VERSION ""

NS_ :

BS_:

BU_: MPC

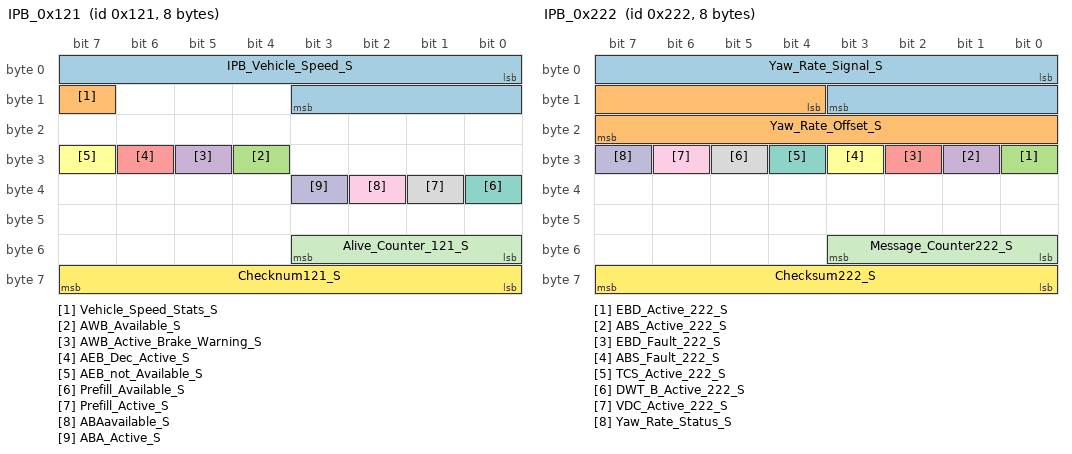
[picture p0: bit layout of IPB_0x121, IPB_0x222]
BO_ 289 IPB_0x121: 8 Vector__XXX
 SG_ IPB_Vehicle_Speed_S : 0|12@1+ (0.06875,0) [0|281.4625] "km/h"  MPC
 SG_ Vehicle_Speed_Stats_S : 15|1@1+ (1,0) [0|1] ""  MPC
 SG_ AWB_Available_S : 28|1@1+ (1,0) [0|1] ""  MPC
 SG_ AWB_Active_Brake_Warning_S : 29|1@1+ (1,0) [0|1] ""  MPC
 SG_ AEB_Dec_Active_S : 30|1@1+ (1,0) [0|1] ""  MPC
 SG_ AEB_not_Available_S : 31|1@1+ (1,0) [0|1] ""  MPC
 SG_ Prefill_Available_S : 32|1@1+ (1,0) [0|1] ""  MPC
 SG_ Prefill_Active_S : 33|1@1+ (1,0) [0|1] ""  MPC
 SG_ ABAavailable_S : 34|1@1+ (1,0) [0|1] ""  MPC
 SG_ ABA_Active_S : 35|1@1+ (1,0) [0|1] ""  MPC
 SG_ Alive_Counter_121_S : 48|4@1+ (1,0) [0|15] ""  MPC
 SG_ Checknum121_S : 56|8@1+ (1,0) [0|255] ""  MPC

BO_ 291 IPB_0x123: 8 Vector__XXX
 SG_ HHC_Fault_S : 0|1@1+ (1,0) [0|1] "" Vector__XXX
 SG_ ATS_Ctrl_Status_S : 1|1@1+ (1,0) [0|1] "" Vector__XXX
 SG_ Brake_Fluid_Warning_S : 2|2@1+ (1,0) [0|3] "" Vector__XXX
 SG_ IPB_Sport_Model_S : 4|1@1+ (1,0) [0|1] "" Vector__XXX
 SG_ IPB_Func_Mode_S : 5|2@1+ (1,0) [0|3] "" Vector__XXX
 SG_ Mmot_Tar_Fast_FA_S : 8|16@1+ (1,-12000) [-12000|12000] "NM" Vector__XXX
 SG_ Mmot_Tar_Slow_S : 24|16@1+ (1,-12000) [-12000|12000] "NM" Vector__XXX
 SG_ HDC_Failure_S : 40|1@1+ (1,0) [0|1] "" Vector__XXX
 SG_ HDC_CtrlStatus_S : 41|2@1+ (1,0) [0|3] ""  MPC
 SG_ Brake_Pedal_Status_S : 43|2@1+ (1,0) [0|3] ""  MPC
 SG_ Basc_Front_S : 45|1@1+ (1,0) [0|1] "" Vector__XXX
 SG_ Clutch_Pedal_Status_S : 46|1@1+ (1,0) [0|1] "" Vector__XXX
 SG_ ACMH_Fault_S : 47|1@1+ (1,0) [0|1] "" Vector__XXX
 SG_ Counter123_S : 48|4@1+ (1,0) [0|15] ""  MPC
 SG_ ESP_OFF_S : 52|1@1+ (1,0) [0|1] ""  MPC
 SG_ ESP_Active_S : 53|1@1+ (1,0) [0|1] ""  MPC
 SG_ TCS_Fault_S : 54|1@1+ (1,0) [0|1] ""  MPC
 SG_ VDC_Fault_S : 55|1@1+ (1,0) [0|1] ""  MPC
 SG_ Checksum123_S : 56|8@1+ (1,0) [0|255] ""  MPC

BO_ 546 IPB_0x222: 8 Vector__XXX
 SG_ Yaw_Rate_Signal_S : 0|12@1+ (0.002132603,-2.0943) [-2.0943|2.0943] "rad/s"  MPC
 SG_ Yaw_Rate_Offset_S : 12|12@1+ (0.002132603,-0.13) [-0.13|0.13] "rad/s"  MPC
 SG_ EBD_Active_222_S : 24|1@1+ (1,0) [0|1] ""  MPC
 SG_ ABS_Active_222_S : 25|1@1+ (1,0) [0|1] ""  MPC
 SG_ EBD_Fault_222_S : 26|1@1+ (1,0) [0|1] ""  MPC
 SG_ ABS_Fault_222_S : 27|1@1+ (1,0) [0|1] ""  MPC
 SG_ TCS_Active_222_S : 28|1@1+ (1,0) [0|1] ""  MPC
 SG_ DWT_B_Active_222_S : 29|1@1+ (1,0) [0|1] ""  MPC
 SG_ VDC_Active_222_S : 30|1@1+ (1,0) [0|1] ""  MPC
 SG_ Yaw_Rate_Status_S : 31|1@1+ (1,0) [0|1] ""  MPC
 SG_ Message_Counter222_S : 48|4@1+ (1,0) [0|15] ""  MPC
 SG_ Checksum222_S : 56|8@1+ (1,0) [0|255] ""  MPC

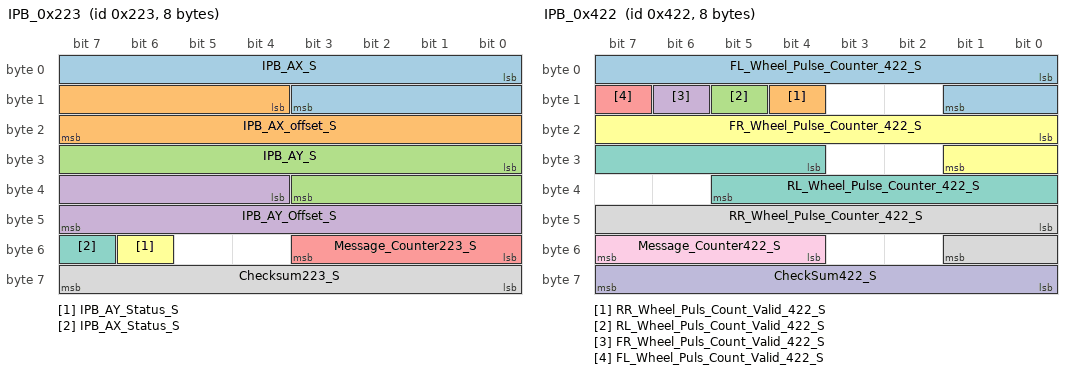
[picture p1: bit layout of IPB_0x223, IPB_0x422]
BO_ 547 IPB_0x223: 8 Vector__XXX
 SG_ IPB_AX_S : 0|12@1+ (0.027126736,-21.593) [-21.593|21.593] "m/s2"  MPC
 SG_ IPB_AX_offset_S : 12|12@1+ (0.027126736,-21.593) [-21.593|21.593] "m/s2"  MPC
 SG_ IPB_AY_S : 24|12@1+ (0.027126736,-21.593) [-21.593|21.593] "m/s2"  MPC
 SG_ IPB_AY_Offset_S : 36|12@1+ (0.027126736,-21.593) [-21.593|21.593] "m/s2"  MPC
 SG_ Message_Counter223_S : 48|4@1+ (1,0) [0|15] ""  MPC
 SG_ IPB_AY_Status_S : 54|1@1+ (1,0) [0|1] ""  MPC
 SG_ IPB_AX_Status_S : 55|1@1+ (1,0) [0|1] ""  MPC
 SG_ Checksum223_S : 56|8@1+ (1,0) [0|255] ""  MPC

BO_ 544 IPB_0x220: 8 Vector__XXX
 SG_ RR_Wheel_Drive_Direction_S : 0|2@1+ (1,0) [0|3] ""  MPC
 SG_ RL_Wheel_Drive_Direction_S : 2|2@1+ (1,0) [0|3] ""  MPC
 SG_ FR_Wheel_Drive_Direction_S : 4|2@1+ (1,0) [0|3] ""  MPC
 SG_ FL_Wheel_Drive_Direction_S : 6|2@1+ (1,0) [0|3] ""  MPC
 SG_ Active_Vehicle_Hold_S : 8|1@1+ (1,0) [0|1] ""  MPC
 SG_ VLC_Available_S : 9|1@1+ (1,0) [0|1] ""  MPC
 SG_ VLC_Active_S : 10|1@1+ (1,0) [0|1] ""  MPC
 SG_ VLC_Fail_S : 11|1@1+ (1,0) [0|1] ""  MPC
 SG_ No_Brake_Force_S : 12|1@1+ (1,0) [0|1] ""  MPC
 SG_ IPB_Request_EPB_S : 13|2@1+ (1,0) [0|3] "" Vector__XXX
 SG_ QDC_ACC_S : 15|1@1+ (1,0) [0|1] ""  MPC
 SG_ ECD_Temp_Off_S : 16|1@1+ (1,0) [0|1] ""  MPC
 SG_ Vlc_Prevent_Fuel_Cut_Off_S : 17|1@1+ (1,0) [0|1] "" Vector__XXX
 SG_ Vehicle_Stand_Still_S : 18|2@1+ (1,0) [0|3] ""  MPC
 SG_ FL_Wheel_Drive_Direct_Stat_S : 20|1@1+ (1,0) [0|1] ""  MPC
 SG_ FR_Wheel_Drive_Direct_Stat_S : 21|1@1+ (1,0) [0|1] ""  MPC
 SG_ RL_Wheel_Drive_Direct_Stat_S : 22|1@1+ (1,0) [0|1] ""  MPC
 SG_ RR_Wheel_Drive_Direct_Stat_S : 23|1@1+ (1,0) [0|1] ""  MPC
 SG_ VLC_Internal_Targ_Accel_S : 24|8@1+ (0.05,-7) [-7|5.75] "m/s2"  MPC
 SG_ VLC_Torque_Request_Value_S : 32|16@1+ (1,-12000) [-12000|12000] "NM" Vector__XXX
 SG_ Message_Counter220_S : 48|4@1+ (1,0) [0|15] ""  MPC
 SG_ VLC_Torque_Request_Status_S : 52|1@1+ (1,0) [0|1] ""  MPC
 SG_ CDD_Available_S : 53|1@1+ (1,0) [0|1] ""  MPC
 SG_ CDD_Active_S : 54|1@1+ (1,0) [0|1] ""  MPC
 SG_ CDD_Fail_S : 55|1@1+ (1,0) [0|1] ""  MPC
 SG_ CheckSum220_S : 56|8@1+ (1,0) [0|255] ""  MPC

BO_ 1058 IPB_0x422: 8 Vector__XXX
 SG_ FL_Wheel_Pulse_Counter_422_S : 0|10@1+ (1,0) [0|1022] ""  MPC
 SG_ RR_Wheel_Puls_Count_Valid_422_S : 12|1@1+ (1,0) [0|1] ""  MPC
 SG_ RL_Wheel_Puls_Count_Valid_422_S : 13|1@1+ (1,0) [0|1] ""  MPC
 SG_ FR_Wheel_Puls_Count_Valid_422_S : 14|1@1+ (1,0) [0|1] ""  MPC
 SG_ FL_Wheel_Puls_Count_Valid_422_S : 15|1@1+ (1,0) [0|1] ""  MPC
 SG_ FR_Wheel_Pulse_Counter_422_S : 16|10@1+ (1,0) [0|1022] ""  MPC
 SG_ RL_Wheel_Pulse_Counter_422_S : 28|10@1+ (1,0) [0|1022] ""  MPC
 SG_ RR_Wheel_Pulse_Counter_422_S : 40|10@1+ (1,0) [0|1022] ""  MPC
 SG_ Message_Counter422_S : 52|4@1+ (1,0) [0|15] ""  MPC
 SG_ CheckSum422_S : 56|8@1+ (1,0) [0|255] ""  MPC

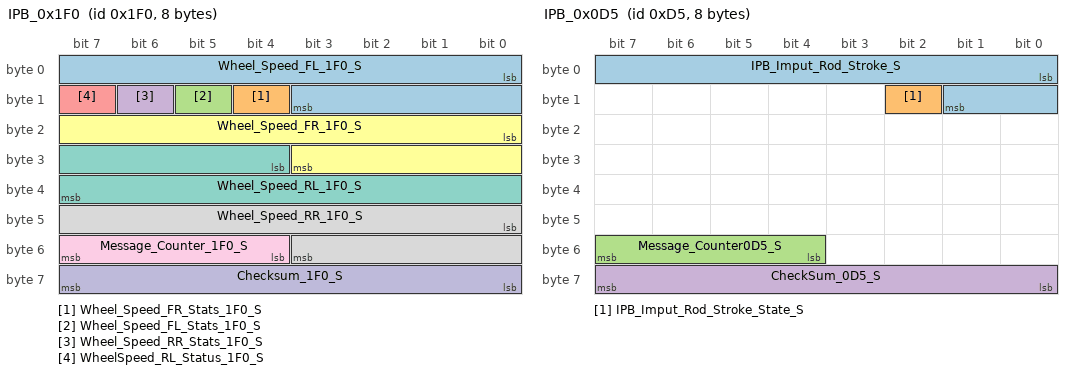
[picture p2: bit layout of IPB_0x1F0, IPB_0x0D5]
BO_ 496 IPB_0x1F0: 8 Vector__XXX
 SG_ Wheel_Speed_FL_1F0_S : 0|12@1+ (0.06875,0) [0|281.4625] "km/h"  MPC
 SG_ Wheel_Speed_FR_Stats_1F0_S : 12|1@1+ (1,0) [0|1] ""  MPC
 SG_ Wheel_Speed_FL_Stats_1F0_S : 13|1@1+ (1,0) [0|1] ""  MPC
 SG_ Wheel_Speed_RR_Stats_1F0_S : 14|1@1+ (1,0) [0|1] ""  MPC
 SG_ WheelSpeed_RL_Status_1F0_S : 15|1@1+ (1,0) [0|1] ""  MPC
 SG_ Wheel_Speed_FR_1F0_S : 16|12@1+ (0.06875,0) [0|281.4625] "km/h"  MPC
 SG_ Wheel_Speed_RL_1F0_S : 28|12@1+ (0.06875,0) [0|281.4625] "km/h"  MPC
 SG_ Wheel_Speed_RR_1F0_S : 40|12@1+ (0.06875,0) [0|281.4625] "km/h"  MPC
 SG_ Message_Counter_1F0_S : 52|4@1+ (1,0) [0|15] ""  MPC
 SG_ Checksum_1F0_S : 56|8@1+ (1,0) [0|255] ""  MPC

BO_ 213 IPB_0x0D5: 8 Vector__XXX
 SG_ IPB_Imput_Rod_Stroke_S : 0|10@1+ (0.05,-5) [-5|46.15] "mm"  MPC
 SG_ IPB_Imput_Rod_Stroke_State_S : 10|1@1+ (1,0) [0|1] ""  MPC
 SG_ Message_Counter0D5_S : 52|4@1+ (1,0) [0|15] ""  MPC
 SG_ CheckSum_0D5_S : 56|8@1+ (1,0) [0|255] ""  MPC

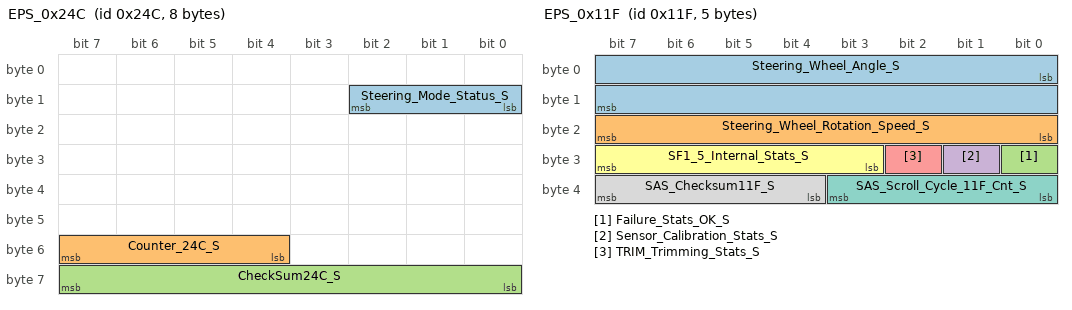
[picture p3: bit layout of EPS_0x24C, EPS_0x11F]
BO_ 588 EPS_0x24C: 8 Vector__XXX
 SG_ Steering_Mode_Status_S : 8|3@1+ (1,0) [0|15] ""  MPC
 SG_ Counter_24C_S : 52|4@1+ (1,0) [0|15] ""  MPC
 SG_ CheckSum24C_S : 56|8@1+ (1,0) [0|255] ""  MPC

BO_ 287 EPS_0x11F: 5 Vector__XXX
 SG_ Steering_Wheel_Angle_S : 0|16@1- (0.1,0) [-780|779.9] "度"  MPC
 SG_ Steering_Wheel_Rotation_Speed_S : 16|8@1+ (4,0) [0|1016] "°/s"  MPC
 SG_ Failure_Stats_OK_S : 24|1@1+ (1,0) [0|1] ""  MPC
 SG_ Sensor_Calibration_Stats_S : 25|1@1+ (1,0) [0|1] ""  MPC
 SG_ TRIM_Trimming_Stats_S : 26|1@1+ (1,0) [0|1] ""  MPC
 SG_ SF1_5_Internal_Stats_S : 27|5@1+ (1,0) [0|31] ""  MPC
 SG_ SAS_Scroll_Cycle_11F_Cnt_S : 32|4@1+ (1,0) [0|15] ""  MPC
 SG_ SAS_Checksum11F_S : 36|4@1+ (1,0) [0|15] ""  MPC

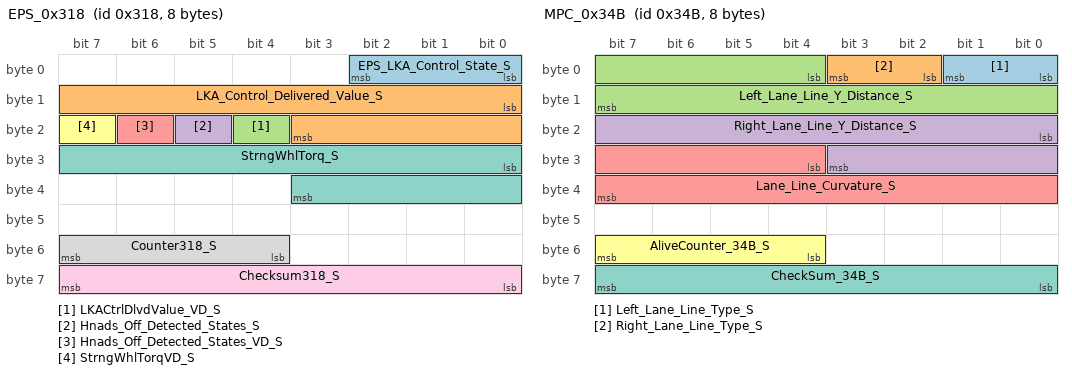
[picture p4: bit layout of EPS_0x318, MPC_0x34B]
BO_ 792 EPS_0x318: 8 Vector__XXX
 SG_ EPS_LKA_Control_State_S : 0|3@1+ (1,0) [0|7] ""  MPC
 SG_ LKA_Control_Delivered_Value_S : 8|12@1- (0.01,0) [-5|-5] "Nm"  MPC
 SG_ LKACtrlDlvdValue_VD_S : 20|1@1+ (1,0) [0|1] ""  MPC
 SG_ Hnads_Off_Detected_States_S : 21|1@1+ (1,0) [0|1] ""  MPC
 SG_ Hnads_Off_Detected_States_VD_S : 22|1@1+ (1,0) [0|1] ""  MPC
 SG_ StrngWhlTorqVD_S : 23|1@1+ (1,0) [0|1] ""  MPC
 SG_ StrngWhlTorq_S : 24|12@1- (0.01,0) [-12.5|12.5] "Nm"  MPC
 SG_ Counter318_S : 52|4@1+ (1,0) [0|15] ""  MPC
 SG_ Checksum318_S : 56|8@1+ (1,0) [0|255] ""  MPC

BO_ 790 MPC_0x316: 8 MPC
 SG_ RSF_Output_Speed_Limit_S : 40|8@1+ (1,0) [0|255] "" Vector__XXX
 SG_ RSF_function_status_S : 29|3@1+ (1,0) [0|3] "" Vector__XXX
 SG_ RSF_Output_Speed_Limit_Unit_S : 32|2@1+ (1,0) [0|3] "" Vector__XXX
 SG_ Over_Temperature : 15|1@1+ (1,0) [0|1] "" Vector__XXX
 SG_ Left_Line_Tracking_Status_S : 4|2@1+ (1,0) [0|3] "" Vector__XXX
 SG_ Lane_Assistant_Mode_Status_S : 6|2@1+ (1,0) [0|3] "" Vector__XXX
 SG_ LKS_Sensitivity_S : 8|2@1+ (1,0) [0|3] "" Vector__XXX
 SG_ MPC_Take_Over_Req_S : 10|1@1+ (1,0) [0|1] "" Vector__XXX
 SG_ LDP_LDW_Camera_Blocked_S : 11|1@1+ (1,0) [0|1] "" Vector__XXX
 SG_ LDP_Fault_S : 12|1@1+ (1,0) [0|1] "" Vector__XXX
 SG_ LDW_fault1_S : 13|1@1+ (1,0) [0|1] "" Vector__XXX
 SG_ ACC_AEB_Camera_Blocked_Infro_S : 14|1@1+ (1,0) [0|1] "" Vector__XXX
 SG_ Output_LKS_torque_request_S : 16|11@1- (0.01,0) [-10.24|10.23] "Nm" Vector__XXX
 SG_ LKS_torque_request_staus_S : 27|2@1+ (1,0) [0|3] "" Vector__XXX
 SG_ Right_Line_Tracking_Stats_S : 34|2@1+ (1,0) [0|3] "" Vector__XXX
 SG_ TJA_ICA_function_status_S : 36|3@1+ (1,0) [0|7] "" Vector__XXX
 SG_ ALL_Function_Camera_Bloc_Infro_S : 39|1@1+ (1,0) [0|1] "" Vector__XXX
 SG_ LDW_Warning_Mode_Stats_S : 48|2@1+ (1,0) [0|3] "" Vector__XXX
 SG_ MPC_Take_Over_Req1_S : 50|2@1+ (1,0) [0|3] "" Vector__XXX
 SG_ Message_Alive_Counter316_S : 52|4@1+ (1,0) [0|15] "" Vector__XXX
 SG_ Messge_Checksum316_S : 56|8@1+ (1,0) [0|255] "" Vector__XXX

BO_ 1074 MPC_0x432: 8 MPC
 SG_ ADS_System_Status_S : 28|4@1+ (1,0) [0|15] "" Vector__XXX
 SG_ CSW_Assemble_Status_S : 27|1@1+ (1,0) [0|1] "" Vector__XXX
 SG_ UNP_Assemble_Status_S : 26|1@1+ (1,0) [0|1] "" Vector__XXX
 SG_ FCTB_Assemble_Status_S : 17|1@1+ (1,0) [0|1] "" Vector__XXX
 SG_ ACC_Assemble_Status_S : 0|1@1+ (1,0) [0|1] "" Vector__XXX
 SG_ AEB_Assemble_Status_S : 1|1@1+ (1,0) [0|1] "" Vector__XXX
 SG_ FCW_Assemble_Status_S : 2|1@1+ (1,0) [0|1] "" Vector__XXX
 SG_ HMA_Assemble_Status_S : 3|1@1+ (1,0) [0|1] "" Vector__XXX
 SG_ LDW_Assemble_Status_S : 4|1@1+ (1,0) [0|1] "" Vector__XXX
 SG_ LKS_Assemble_Status_S : 5|1@1+ (1,0) [0|1] "" Vector__XXX
 SG_ TSR_Assemble_Status_S : 6|1@1+ (1,0) [0|1] "" Vector__XXX
 SG_ TJA_ICA_Assemble_Status_S : 7|1@1+ (1,0) [0|1] "" Vector__XXX
 SG_ Module_Manufacturer_S : 8|4@1+ (1,0) [0|15] "" Vector__XXX
 SG_ LDW_Warning_Conf_Exchange_S : 12|1@1+ (1,0) [0|1] "" Vector__XXX
 SG_ TJA_ICA_SoftKeys_S : 13|1@1+ (1,0) [0|1] "" Vector__XXX
 SG_ LDP_Assemble_Status_S : 14|1@1+ (1,0) [0|1] "" Vector__XXX
 SG_ ELK_Assemble_Status_S : 15|1@1+ (1,0) [0|1] "" Vector__XXX
 SG_ FCTA_Assemble_Status_S : 16|1@1+ (1,0) [0|1] "" Vector__XXX
 SG_ ISLI_Assemble_Statue_S : 18|1@1+ (1,0) [0|1] "" Vector__XXX
 SG_ HNP_Assemble_Status_S : 19|1@1+ (1,0) [0|1] "" Vector__XXX
 SG_ ILCA_Assemble_Status_S : 20|1@1+ (1,0) [0|1] "" Vector__XXX
 SG_ TLA_Assemble_Status_S : 21|1@1+ (1,0) [0|1] "" Vector__XXX
 SG_ ISLC_Assemble_Status_S : 22|1@1+ (1,0) [0|1] "" Vector__XXX
 SG_ ESA_Assemble_Status_S : 23|1@1+ (1,0) [0|1] "" Vector__XXX
 SG_ FCW_UI_Assemble_Status_S : 24|1@1+ (1,0) [0|1] "" Vector__XXX
 SG_ Meter_Display_Mode_S : 25|1@1+ (1,0) [0|1] "" Vector__XXX

BO_ 884 MPC_0x374: 8 MPC
 SG_ Target_Type_374s5_S m5 : 44|4@1+ (1,0) [0|15] "" Vector__XXX
 SG_ Target_State_B1_374s5_S m5 : 43|1@1+ (1,0) [0|1] "" Vector__XXX
 SG_ Target_State_B6_374s5_S m5 : 40|2@1+ (1,0) [0|3] "" Vector__XXX
 SG_ Lock_Target_Ordinate_374s5_S m5 : 16|8@1+ (1,-100) [-100|100] "pot" Vector__XXX
 SG_ Lock_Target_Abscissa_374s5_S m5 : 8|8@1+ (1,-100) [-100|100] "pot" Vector__XXX
 SG_ Goal_Late_Relative_Spd_374s5_S m5 : 32|8@1+ (1,0) [0|254] "km/h" Vector__XXX
 SG_ Goal_Length_Relative_Spd_374s5_S m5 : 24|8@1+ (1,0) [0|254] "km/h" Vector__XXX
 SG_ AliveCounter_374s5_S m5 : 52|4@1+ (1,0) [0|15] "" Vector__XXX
 SG_ CheckSum_374s5_S m5 : 56|8@1+ (1,0) [0|255] "" Vector__XXX
 SG_ Child_ID_374_S M : 0|8@1+ (1,0) [0|255] "" Vector__XXX
 SG_ Lock_Target_Abscissa_374s1_S m1 : 8|8@1+ (1,-100) [-100|100] "pot" Vector__XXX
 SG_ Lock_Target_Ordinate_374s1_S m1 : 16|8@1+ (1,-100) [-100|100] "pot" Vector__XXX
 SG_ Goal_Length_Relative_Spd_374s1_S m1 : 24|8@1+ (1,0) [0|254] "km/h" Vector__XXX
 SG_ Goal_Late_Relative_Spd_374s1_S m1 : 32|8@1+ (1,0) [0|254] "km/h" Vector__XXX
 SG_ Target_State_B6_374s1_S m1 : 40|2@1+ (1,0) [0|3] "" Vector__XXX
 SG_ Target_State_B1_374s1_S m1 : 43|1@1+ (1,0) [0|1] "" Vector__XXX
 SG_ Target_Type_374s1_S m1 : 44|4@1+ (1,0) [0|15] "" Vector__XXX
 SG_ AliveCounter_374s1_S m1 : 52|4@1+ (1,0) [0|15] "" Vector__XXX
 SG_ CheckSum_374s1_S m1 : 56|8@1+ (1,0) [0|255] "" Vector__XXX
 SG_ Lock_Target_Abscissa_374s2_S m2 : 8|8@1+ (1,-100) [-100|100] "pot" Vector__XXX
 SG_ Lock_Target_Ordinate_374s2_S m2 : 16|8@1+ (1,-100) [-100|100] "pot" Vector__XXX
 SG_ Goal_Length_Relative_Spd_374s2_S m2 : 24|8@1+ (1,0) [0|254] "km/h" Vector__XXX
 SG_ Goal_Late_Relative_Spd_374s2_S m2 : 32|8@1+ (1,0) [0|254] "km/h" Vector__XXX
 SG_ Target_State_B6_374s2_S m2 : 40|2@1+ (1,0) [0|3] "" Vector__XXX
 SG_ Target_State_B1_374s2_S m2 : 43|1@1+ (1,0) [0|1] "" Vector__XXX
 SG_ Target_Type_374s2_S m2 : 44|4@1+ (1,0) [0|15] "" Vector__XXX
 SG_ AliveCounter_374s2_S m2 : 52|4@1+ (1,0) [0|15] "" Vector__XXX
 SG_ CheckSum_374s2_S m2 : 56|8@1+ (1,0) [0|255] "" Vector__XXX
 SG_ Lock_Target_Abscissa_374s3_S m3 : 8|8@1+ (1,-100) [-100|100] "pot" Vector__XXX
 SG_ Lock_Target_Ordinate_374s3_S m3 : 16|8@1+ (1,-100) [-100|100] "pot" Vector__XXX
 SG_ Goal_Length_Relative_Spd_374s3_S m3 : 24|8@1+ (1,0) [0|254] "km/h" Vector__XXX
 SG_ Goal_Late_Relative_Spd_374s3_S m3 : 32|8@1+ (1,0) [0|254] "km/h" Vector__XXX
 SG_ Target_State_B6_374s3_S m3 : 40|2@1+ (1,0) [0|3] "" Vector__XXX
 SG_ Target_State_B1_374s3_S m3 : 43|1@1+ (1,0) [0|1] "" Vector__XXX
 SG_ Target_Type_374s3_S m3 : 44|4@1+ (1,0) [0|15] "" Vector__XXX
 SG_ AliveCounter_374s3_S m3 : 52|4@1+ (1,0) [0|15] "" Vector__XXX
 SG_ CheckSum_374s3_S m3 : 56|8@1+ (1,0) [0|255] "" Vector__XXX
 SG_ Lock_Target_Abscissa_374s4_S m4 : 8|8@1+ (1,-100) [-100|100] "pot" Vector__XXX
 SG_ Lock_Target_Ordinate_374s4_S m4 : 16|8@1+ (1,-100) [-100|100] "pot" Vector__XXX
 SG_ Goal_Length_Relative_Spd_374s4_S m4 : 24|8@1+ (1,0) [0|254] "km/h" Vector__XXX
 SG_ Goal_Late_Relative_Spd_374s4_S m4 : 32|8@1+ (1,0) [0|254] "km/h" Vector__XXX
 SG_ Target_State_B6_374s4_S m4 : 40|2@1+ (1,0) [0|3] "" Vector__XXX
 SG_ Target_State_B1_374s4_S m4 : 43|1@1+ (1,0) [0|1] "" Vector__XXX
 SG_ Target_Type_374s4_S m4 : 44|4@1+ (1,0) [0|15] "" Vector__XXX
 SG_ AliveCounter_374s4_S m4 : 52|4@1+ (1,0) [0|15] "" Vector__XXX
 SG_ CheckSum_374s4_S m4 : 56|8@1+ (1,0) [0|255] "" Vector__XXX

BO_ 843 MPC_0x34B: 8 MPC
 SG_ Left_Lane_Line_Type_S : 0|2@1+ (1,0) [0|3] "" Vector__XXX
 SG_ Right_Lane_Line_Type_S : 2|2@1+ (1,0) [0|3] "" Vector__XXX
 SG_ Left_Lane_Line_Y_Distance_S : 4|12@1+ (0.00390625,-8) [-8|7.9960938] "" Vector__XXX
 SG_ Right_Lane_Line_Y_Distance_S : 16|12@1+ (0.00390625,-8) [-8|7.9960938] "" Vector__XXX
 SG_ Lane_Line_Curvature_S : 28|12@1+ (1.5E-005,-0.030705) [-0.030705|0.030705] "" Vector__XXX
 SG_ AliveCounter_34B_S : 52|4@1+ (1,0) [0|15] "" Vector__XXX
 SG_ CheckSum_34B_S : 56|8@1+ (1,0) [0|255] "" Vector__XXX

BO_ 813 MPC_0x32D: 8 MPC
 SG_ MRR_Modulation_Status_S : 54|2@1+ (1,0) [0|3] "" Vector__XXX
 SG_ Front_Radar_FCTB_Warning_S : 41|3@1+ (1,0) [0|7] "" Vector__XXX
 SG_ Set_Speed_S : 0|9@1+ (5,0) [0|2555] "km/h" Vector__XXX
 SG_ Obj_Valid_S : 9|1@1+ (1,0) [0|1] "" Vector__XXX
 SG_ Tau_Gap_Set_S : 10|3@1+ (1,0) [0|7] "" Vector__XXX
 SG_ Dx_Tar_Obj_S : 13|3@1+ (1,0) [0|7] "" Vector__XXX
 SG_ PCW_Pre_Warning_S : 16|1@1+ (1,0) [0|1] "" Vector__XXX
 SG_ PCW_Latent_Warning_S : 17|1@1+ (1,0) [0|1] "" Vector__XXX
 SG_ PCW_State_S : 18|1@1+ (1,0) [0|1] "" Vector__XXX
 SG_ ACC_Mode_Display_S : 19|3@1+ (1,0) [0|7] "" Vector__XXX
 SG_ ACC_State_S : 22|1@1+ (1,0) [0|1] "" Vector__XXX
 SG_ Take_Over_Req_S : 23|1@1+ (1,0) [0|1] "" Vector__XXX
 SG_ Speed_Unit_Set_S : 24|2@1+ (1,0) [0|3] "" Vector__XXX
 SG_ CCR_AEB_Error_S : 26|1@1+ (1,0) [0|1] "" Vector__XXX
 SG_ ACC_Text_Info_For_Driver_S : 27|5@1+ (1,0) [0|31] "" Vector__XXX
 SG_ CCR_FCW_Error_S : 32|1@1+ (1,0) [0|1] "" Vector__XXX
 SG_ Pedestrian_FCW_Brak_Error_S : 33|1@1+ (1,0) [0|1] "" Vector__XXX
 SG_ Acute_Warning_S : 35|1@1+ (1,0) [0|1] "" Vector__XXX
 SG_ AEB_State_S : 36|1@1+ (1,0) [0|1] "" Vector__XXX
 SG_ PCW_Level_Feedback_S : 37|2@1+ (1,0) [0|3] "" Vector__XXX
 SG_ ACC_Mode_Display1_S : 44|4@1+ (1,0) [0|15] "" Vector__XXX
 SG_ Alive_Counter32D_S : 48|4@1+ (1,0) [0|15] "" Vector__XXX
 SG_ Checksum32D_S : 56|8@1+ (1,0) [0|255] "" Vector__XXX

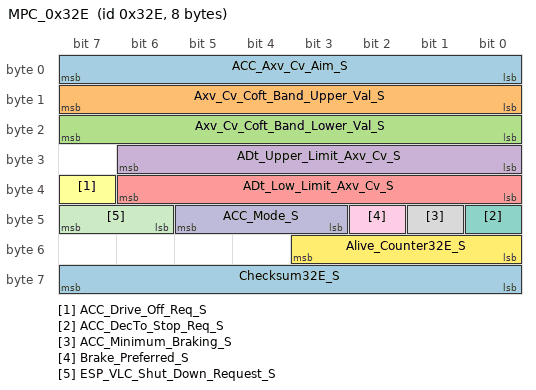
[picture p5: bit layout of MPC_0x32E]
BO_ 814 MPC_0x32E: 8 MPC
 SG_ ACC_Axv_Cv_Aim_S : 0|8@1+ (0.05,-5) [-5|7.75] "m/s2" Vector__XXX
 SG_ Axv_Cv_Coft_Band_Upper_Val_S : 8|8@1+ (0.05,-5) [-5|7.75] "m/s2" Vector__XXX
 SG_ Axv_Cv_Coft_Band_Lower_Val_S : 16|8@1+ (0.05,-5) [-5|7.75] "m/s2" Vector__XXX
 SG_ ADt_Upper_Limit_Axv_Cv_S : 24|7@1+ (0.2,0) [0|16] "m/s3" Vector__XXX
 SG_ ADt_Low_Limit_Axv_Cv_S : 32|7@1+ (0.2,-16) [-16|0] "m/s3" Vector__XXX
 SG_ ACC_Drive_Off_Req_S : 39|1@1+ (1,0) [0|1] "" Vector__XXX
 SG_ ACC_DecTo_Stop_Req_S : 40|1@1+ (1,0) [0|1] "" Vector__XXX
 SG_ ACC_Minimum_Braking_S : 41|1@1+ (1,0) [0|1] "" Vector__XXX
 SG_ Brake_Preferred_S : 42|1@1+ (1,0) [0|1] "" Vector__XXX
 SG_ ACC_Mode_S : 43|3@1+ (1,0) [0|7] "" Vector__XXX
 SG_ ESP_VLC_Shut_Down_Request_S : 46|2@1+ (1,0) [0|3] "" Vector__XXX
 SG_ Alive_Counter32E_S : 48|4@1+ (1,0) [0|15] "" Vector__XXX
 SG_ Checksum32E_S : 56|8@1+ (1,0) [0|255] "" Vector__XXX

BO_ 815 MPC_0x32F: 8 MPC
 SG_ MRR_MRC_Request_S : 44|2@1+ (1,0) [0|3] "" Vector__XXX
 SG_ MRR_SOS_Request_S : 42|2@1+ (1,0) [0|3] "" Vector__XXX
 SG_ SeatbeltControl_Request_S : 40|2@1+ (1,0) [0|7] "" Vector__XXX
 SG_ ELK_OT_status_S : 24|2@1+ (1,0) [0|3] "" Vector__XXX
 SG_ ABA_Level_S : 21|2@1+ (1,0) [0|3] ""  MPC
 SG_ ABA_Available_S : 20|1@1+ (1,0) [0|1] ""  MPC
 SG_ AEB_Ax_Tar_S : 0|16@1+ (0.0004882,-16) [-16|16] "m/s2" Vector__XXX
 SG_ Req_EBA_Decel_Ctrl_S : 16|1@1+ (1,0) [0|1] "" Vector__XXX
 SG_ ESP_Prefill_Req_S : 18|1@1+ (1,0) [0|1] "" Vector__XXX
 SG_ AWB_Request_S : 19|1@1+ (1,0) [0|1] "" Vector__XXX
 SG_ AEB_DecCtrl_Request_S : 23|1@1+ (1,0) [0|1] "" Vector__XXX
 SG_ AWB_Level_S : 28|4@1+ (1,0) [0|15] "" Vector__XXX
 SG_ Req_ESC_Ctrl_Veh_S : 32|1@1+ (1,0) [0|1] "" Vector__XXX
 SG_ ISLC_Sts_S : 33|1@1+ (1,0) [0|1] "" Vector__XXX
 SG_ ELK_status_S : 34|2@1+ (1,0) [0|3] "" Vector__XXX
 SG_ ISLC_Warnning_S : 36|1@1+ (1,0) [0|1] "" Vector__XXX
 SG_ ELK_Take_Over_Req_S : 37|2@1+ (1,0) [0|3] "" Vector__XXX
 SG_ Alive_Counter32F_S : 48|4@1+ (1,0) [0|15] "" Vector__XXX
 SG_ Checksum32F_S : 56|8@1+ (1,0) [0|255] "" Vector__XXX

CM_ SG_ 289 IPB_Vehicle_Speed_S "IPB_Vehicle_speed";
CM_ SG_ 289 Vehicle_Speed_Stats_S "IPB_VehicleSpeed_Status";
CM_ SG_ 289 AWB_Available_S "AWBavailable";
CM_ SG_ 289 AWB_Active_Brake_Warning_S "自动制动警告AWBactive";
CM_ SG_ 289 AEB_Dec_Active_S "AEBdecActive";
CM_ SG_ 289 AEB_not_Available_S "自动紧急制动有效状态AEBnotAvailable";
CM_ SG_ 289 Prefill_Available_S "PrefillAvailable";
CM_ SG_ 289 Prefill_Active_S "PrefillActive";
CM_ SG_ 289 ABAavailable_S "ABAavailable";
CM_ SG_ 289 ABA_Active_S "ABAactive";
CM_ SG_ 289 Alive_Counter_121_S "Alive_counter_121";
CM_ SG_ 289 Checknum121_S "校验码121";
CM_ SG_ 291 HHC_Fault_S "HHC_Fault";
CM_ SG_ 291 ATS_Ctrl_Status_S "ATS_ CtrlStatus";
CM_ SG_ 291 Brake_Fluid_Warning_S "BrakeFluid_Warning";
CM_ SG_ 291 IPB_Sport_Model_S "IPB_Sport_Model";
CM_ SG_ 291 IPB_Func_Mode_S "IPB功能模式";
CM_ SG_ 291 Mmot_Tar_Fast_FA_S "前轴快速降扭MMotTarFast FA（分辨率为1）";
CM_ SG_ 291 Mmot_Tar_Slow_S "前轴慢速降扭MMotTarSlow（分辨率为1）";
CM_ SG_ 291 HDC_Failure_S "HDC_Failure";
CM_ SG_ 291 HDC_CtrlStatus_S "HDC_CtrlStatus";
CM_ SG_ 291 Brake_Pedal_Status_S "Brake Pedal Status";
CM_ SG_ 291 Basc_Front_S "Basc（前轴）";
CM_ SG_ 291 Clutch_Pedal_Status_S "Clutch Pedal Status";
CM_ SG_ 291 ACMH_Fault_S "ACMH_Fault";
CM_ SG_ 291 Counter123_S "Counter123";
CM_ SG_ 291 ESP_OFF_S "ESP_OFF";
CM_ SG_ 291 ESP_Active_S "ESP_Active";
CM_ SG_ 291 TCS_Fault_S "TCS_Fault";
CM_ SG_ 291 VDC_Fault_S "VDC_Fault";
CM_ SG_ 291 Checksum123_S "Checksum123";
CM_ SG_ 546 Yaw_Rate_Signal_S "Yaw Rate Signal";
CM_ SG_ 546 Yaw_Rate_Offset_S "Yaw rate offset";
CM_ SG_ 546 EBD_Active_222_S "EBD_Active_222";
CM_ SG_ 546 ABS_Active_222_S "ABS_Active_222";
CM_ SG_ 546 EBD_Fault_222_S "EBD_Fault_222";
CM_ SG_ 546 ABS_Fault_222_S "ABS_Fault_222";
CM_ SG_ 546 TCS_Active_222_S "TCSActive_222";
CM_ SG_ 546 DWT_B_Active_222_S "DTCActive_222
DTC_Active_222_S";
CM_ SG_ 546 VDC_Active_222_S "VDCActive_222";
CM_ SG_ 546 Yaw_Rate_Status_S "Yaw rate status";
CM_ SG_ 546 Message_Counter222_S "Message counter222";
CM_ SG_ 546 Checksum222_S "Checksum222";
CM_ SG_ 547 IPB_AX_S "IPB_AX";
CM_ SG_ 547 IPB_AX_offset_S "IPB_AX offset";
CM_ SG_ 547 IPB_AY_S "IPB_AY";
CM_ SG_ 547 IPB_AY_Offset_S "IPB_AY Offset";
CM_ SG_ 547 Message_Counter223_S "Message counter 223";
CM_ SG_ 547 IPB_AY_Status_S "IPB_AY status";
CM_ SG_ 547 IPB_AX_Status_S "IPB_AX status";
CM_ SG_ 547 Checksum223_S "Checksum223";
CM_ SG_ 544 RR_Wheel_Drive_Direction_S "右后轮行驶方向";
CM_ SG_ 544 RL_Wheel_Drive_Direction_S "左后轮行驶方向";
CM_ SG_ 544 FR_Wheel_Drive_Direction_S "右前轮行驶方向";
CM_ SG_ 544 FL_Wheel_Drive_Direction_S "左前轮行驶方向";
CM_ SG_ 544 Active_Vehicle_Hold_S "ActiveVehicleHold";
CM_ SG_ 544 VLC_Available_S "VLC_Available";
CM_ SG_ 544 VLC_Active_S "车辆纵向控制状态";
CM_ SG_ 544 VLC_Fail_S "VLCfail";
CM_ SG_ 544 No_Brake_Force_S "NoBrakeForce";
CM_ SG_ 544 IPB_Request_EPB_S "IPB_Request_EPB";
CM_ SG_ 544 QDC_ACC_S "QDCACC";
CM_ SG_ 544 ECD_Temp_Off_S "ECDTempOff";
CM_ SG_ 544 Vlc_Prevent_Fuel_Cut_Off_S "VlcPreventFuelCutOff（预留）";
CM_ SG_ 544 Vehicle_Stand_Still_S "车辆静止标记位";
CM_ SG_ 544 FL_Wheel_Drive_Direct_Stat_S "左前轮行驶方向状态";
CM_ SG_ 544 FR_Wheel_Drive_Direct_Stat_S "右前轮行驶方向状态";
CM_ SG_ 544 RL_Wheel_Drive_Direct_Stat_S "左后轮行驶方向状态";
CM_ SG_ 544 RR_Wheel_Drive_Direct_Stat_S "右后轮行驶方向状态";
CM_ SG_ 544 VLC_Internal_Targ_Accel_S "VLC_InternalTargetACCeleration";
CM_ SG_ 544 VLC_Torque_Request_Value_S "扭矩请求值";
CM_ SG_ 544 Message_Counter220_S "Message counter 220";
CM_ SG_ 544 VLC_Torque_Request_Status_S "扭矩请求值状态";
CM_ SG_ 544 CDD_Available_S "CDD_Available";
CM_ SG_ 544 CDD_Active_S "CDD_Active";
CM_ SG_ 544 CDD_Fail_S "CDD_Fail";
CM_ SG_ 544 CheckSum220_S "CheckSum220";
CM_ SG_ 1058 FL_Wheel_Pulse_Counter_422_S "FL Wheel Pulse Counter_422";
CM_ SG_ 1058 RR_Wheel_Puls_Count_Valid_422_S "RR Wheel Pulse Counter Validity_422";
CM_ SG_ 1058 RL_Wheel_Puls_Count_Valid_422_S "RL Wheel Pulse Counter Validity_422";
CM_ SG_ 1058 FR_Wheel_Puls_Count_Valid_422_S "FR Wheel Pulse Counter Validity_422";
CM_ SG_ 1058 FL_Wheel_Puls_Count_Valid_422_S "FL Wheel Pulse Counter Validity_422";
CM_ SG_ 1058 FR_Wheel_Pulse_Counter_422_S "FR Wheel Pulse Counter_422";
CM_ SG_ 1058 RL_Wheel_Pulse_Counter_422_S "RL Wheel Pulse Counter_422";
CM_ SG_ 1058 RR_Wheel_Pulse_Counter_422_S "RR Wheel Pulse Counter_422";
CM_ SG_ 1058 Message_Counter422_S "Message counter 422";
CM_ SG_ 1058 CheckSum422_S "CheckSum422";
CM_ SG_ 496 Wheel_Speed_FL_1F0_S "WheelSpeed_FL_1F0";
CM_ SG_ 496 Wheel_Speed_FR_Stats_1F0_S "WheelSpeed_FR_Status_1F0";
CM_ SG_ 496 Wheel_Speed_FL_Stats_1F0_S "WheelSpeed_FL_Status_1F0";
CM_ SG_ 496 Wheel_Speed_RR_Stats_1F0_S "WheelSpeed_RR_Status_1F0";
CM_ SG_ 496 WheelSpeed_RL_Status_1F0_S "WheelSpeed_RL_Status_1F0";
CM_ SG_ 496 Wheel_Speed_FR_1F0_S "WheelSpeed_FR_1F0";
CM_ SG_ 496 Wheel_Speed_RL_1F0_S "WheelSpeed_RL_1F0";
CM_ SG_ 496 Wheel_Speed_RR_1F0_S "WheelSpeed_RR_1F0";
CM_ SG_ 496 Message_Counter_1F0_S "Message counter_1F0";
CM_ SG_ 496 Checksum_1F0_S "校验码_1F0";
CM_ SG_ 213 IPB_Imput_Rod_Stroke_S "踏板行程";
CM_ SG_ 213 IPB_Imput_Rod_Stroke_State_S "踏板行程状态";
CM_ SG_ 213 Message_Counter0D5_S "Message counter_0D5";
CM_ SG_ 213 CheckSum_0D5_S "CheckSum_0D5";
CM_ SG_ 588 Steering_Mode_Status_S "转向模式状态";
CM_ SG_ 588 Counter_24C_S "Counter_24C";
CM_ SG_ 588 CheckSum24C_S "校验码24C";
CM_ BO_ 287 "原转角传感器报文";
CM_ SG_ 287 Steering_Wheel_Angle_S "方向盘角度";
CM_ SG_ 287 Steering_Wheel_Rotation_Speed_S "方向盘旋转速度";
CM_ SG_ 287 Failure_Stats_OK_S "Failure_Status OK";
CM_ SG_ 287 Sensor_Calibration_Stats_S "传感器校准状态";
CM_ SG_ 287 TRIM_Trimming_Stats_S "传感器平衡状态";
CM_ SG_ 287 SF1_5_Internal_Stats_S "SF1_5内部状态";
CM_ SG_ 287 SAS_Scroll_Cycle_11F_Cnt_S "滚动循环计数器11F";
CM_ SG_ 287 SAS_Checksum11F_S "校验码11F
temp_result = Byte 1 XOR Byte 2 XOR Byte 3 XOR Byte 4
CHK_SUM = higher nibble(temp_result) XOR lower nibble(temp_result) XOR SAS_Scroll_Cycle_11F_Cnt_S";
CM_ SG_ 792 EPS_LKA_Control_State_S "EPSLKACtrlSt （EPS LKA Control State）";
CM_ SG_ 792 LKA_Control_Delivered_Value_S "LKACtrlDlvdValue（LKA Control Delivered Value）";
CM_ SG_ 792 LKACtrlDlvdValue_VD_S "LKACtrlDlvdValue VD";
CM_ SG_ 792 Hnads_Off_Detected_States_S "HandsOffDetSt（Hnads Off Detected States）";
CM_ SG_ 792 Hnads_Off_Detected_States_VD_S "HandsOffDetStVD";
CM_ SG_ 792 StrngWhlTorqVD_S "StrngWhlTorqVD";
CM_ SG_ 792 StrngWhlTorq_S "StrngWhlTorq（Steering Wheel Torque）";
CM_ SG_ 792 Counter318_S "Counter318";
CM_ SG_ 792 Checksum318_S "Checksum318";
CM_ SG_ 790 RSF_Output_Speed_Limit_S "RSF output speed limitRSF输出速度限制";
CM_ SG_ 790 RSF_function_status_S "RSF function status";
CM_ SG_ 790 RSF_Output_Speed_Limit_Unit_S "RSF output speed limit unitRSF输出速度限制单位";
CM_ SG_ 790 Over_Temperature "前视摄像头过温";
CM_ SG_ 790 Left_Line_Tracking_Status_S "Left line tracking status";
CM_ SG_ 790 Lane_Assistant_Mode_Status_S "车道辅助模式状态";
CM_ SG_ 790 LKS_Sensitivity_S "LKS sensitivity车道保持辅助灵敏度";
CM_ SG_ 790 MPC_Take_Over_Req_S "Take over request to driver驾驶员接管请求";
CM_ SG_ 790 LDP_LDW_Camera_Blocked_S "LKS（LDP）&LDW Camera blocked";
CM_ SG_ 790 LDP_Fault_S "LKS（LDP）fault";
CM_ SG_ 790 LDW_fault1_S "LDW fault";
CM_ SG_ 790 ACC_AEB_Camera_Blocked_Infro_S "ACC/AEB camera blocked infro";
CM_ SG_ 790 Output_LKS_torque_request_S "Output LKS torque request";
CM_ SG_ 790 LKS_torque_request_staus_S "LKS torque request staus";
CM_ SG_ 790 Right_Line_Tracking_Stats_S "Right line tracking status右车道跟踪状态";
CM_ SG_ 790 TJA_ICA_function_status_S "TJA/ICA function status";
CM_ SG_ 790 ALL_Function_Camera_Bloc_Infro_S "ALL function camera blocked Infro";
CM_ SG_ 790 LDW_Warning_Mode_Stats_S "车道偏离报警方式状态";
CM_ SG_ 790 MPC_Take_Over_Req1_S "驾驶员接管请求1";
CM_ SG_ 790 Message_Alive_Counter316_S "Message alive counter316";
CM_ SG_ 790 Messge_Checksum316_S "Messge check sum316";
CM_ SG_ 1074 ADS_System_Status_S "ADS平台系统状态";
CM_ SG_ 1074 CSW_Assemble_Status_S "是否配备弯道超速报警";
CM_ SG_ 1074 UNP_Assemble_Status_S "是否配备城市领航";
CM_ SG_ 1074 FCTB_Assemble_Status_S "是否配备前方穿行制动";
CM_ SG_ 1074 ACC_Assemble_Status_S "是否配备ACC";
CM_ SG_ 1074 AEB_Assemble_Status_S "是否配备AEB";
CM_ SG_ 1074 FCW_Assemble_Status_S "是否配备FCW";
CM_ SG_ 1074 HMA_Assemble_Status_S "是否配备HMA";
CM_ SG_ 1074 LDW_Assemble_Status_S "是否配备LDW";
CM_ SG_ 1074 LKS_Assemble_Status_S "是否配备LKS";
CM_ SG_ 1074 TSR_Assemble_Status_S "是否配备交通标志识别";
CM_ SG_ 1074 TJA_ICA_Assemble_Status_S "是否配备TJA/ICA";
CM_ SG_ 1074 Module_Manufacturer_S "模块厂家";
CM_ SG_ 1074 LDW_Warning_Conf_Exchange_S "LDW是否配备报警方式选择";
CM_ SG_ 1074 TJA_ICA_SoftKeys_S "是否TJA/ICA软开关TJA_ICA_SoftKey_Status_S";
CM_ SG_ 1074 LDP_Assemble_Status_S "是否配备LDP";
CM_ SG_ 1074 ELK_Assemble_Status_S "是否配备ELK";
CM_ SG_ 1074 FCTA_Assemble_Status_S "是否配备前方穿行预警";
CM_ SG_ 1074 ISLI_Assemble_Statue_S "是否配备ISLI超速报警";
CM_ SG_ 1074 HNP_Assemble_Status_S "是否配备高速领航";
CM_ SG_ 1074 ILCA_Assemble_Status_S "是否配备手动变道辅助";
CM_ SG_ 1074 TLA_Assemble_Status_S "是否配备交通灯识别功能";
CM_ SG_ 1074 ISLC_Assemble_Status_S "是否配备智能限速控制";
CM_ SG_ 1074 ESA_Assemble_Status_S "是否配备ESA功能";
CM_ SG_ 1074 FCW_UI_Assemble_Status_S "FCW UI界面显示";
CM_ SG_ 1074 Meter_Display_Mode_S "仪表界面显示 ";
CM_ BO_ 884 "实车相同ID之间50ms，不同子ID之间10ms";
CM_ SG_ 884 Target_Type_374s5_S "目标类型";
CM_ SG_ 884 Target_State_B1_374s5_S "目标状态";
CM_ SG_ 884 Target_State_B6_374s5_S "目标状态";
CM_ SG_ 884 Lock_Target_Ordinate_374s5_S "锁定目标_纵坐标";
CM_ SG_ 884 Lock_Target_Abscissa_374s5_S "锁定目标_横坐标";
CM_ SG_ 884 Goal_Late_Relative_Spd_374s5_S "锁定目标_横向相对速度";
CM_ SG_ 884 Goal_Length_Relative_Spd_374s5_S "锁定目标_纵向相对速度";
CM_ SG_ 884 AliveCounter_374s5_S "AliveCounter374";
CM_ SG_ 884 CheckSum_374s5_S "CheckSum374";
CM_ SG_ 884 Child_ID_374_S "子ID_374";
CM_ SG_ 884 Lock_Target_Abscissa_374s1_S "锁定目标_横坐标";
CM_ SG_ 884 Lock_Target_Ordinate_374s1_S "锁定目标_纵坐标";
CM_ SG_ 884 Goal_Length_Relative_Spd_374s1_S "锁定目标_纵向相对速度";
CM_ SG_ 884 Goal_Late_Relative_Spd_374s1_S "锁定目标_横向相对速度";
CM_ SG_ 884 Target_State_B6_374s1_S "目标状态";
CM_ SG_ 884 Target_State_B1_374s1_S "目标状态";
CM_ SG_ 884 Target_Type_374s1_S "目标类型";
CM_ SG_ 884 AliveCounter_374s1_S "AliveCounter374";
CM_ SG_ 884 CheckSum_374s1_S "CheckSum374";
CM_ SG_ 884 Lock_Target_Abscissa_374s2_S "锁定目标_横坐标";
CM_ SG_ 884 Lock_Target_Ordinate_374s2_S "锁定目标_纵坐标";
CM_ SG_ 884 Goal_Length_Relative_Spd_374s2_S "锁定目标_纵向相对速度";
CM_ SG_ 884 Goal_Late_Relative_Spd_374s2_S "锁定目标_横向相对速度";
CM_ SG_ 884 Target_State_B6_374s2_S "目标状态";
CM_ SG_ 884 Target_State_B1_374s2_S "目标状态";
CM_ SG_ 884 Target_Type_374s2_S "目标类型";
CM_ SG_ 884 AliveCounter_374s2_S "AliveCounter374";
CM_ SG_ 884 CheckSum_374s2_S "CheckSum374";
CM_ SG_ 884 Lock_Target_Abscissa_374s3_S "锁定目标_横坐标";
CM_ SG_ 884 Lock_Target_Ordinate_374s3_S "锁定目标_纵坐标";
CM_ SG_ 884 Goal_Length_Relative_Spd_374s3_S "锁定目标_纵向相对速度";
CM_ SG_ 884 Goal_Late_Relative_Spd_374s3_S "锁定目标_横向相对速度";
CM_ SG_ 884 Target_State_B6_374s3_S "目标状态";
CM_ SG_ 884 Target_State_B1_374s3_S "目标状态";
CM_ SG_ 884 Target_Type_374s3_S "目标类型";
CM_ SG_ 884 AliveCounter_374s3_S "AliveCounter374";
CM_ SG_ 884 CheckSum_374s3_S "CheckSum374";
CM_ SG_ 884 Lock_Target_Abscissa_374s4_S "锁定目标_横坐标";
CM_ SG_ 884 Lock_Target_Ordinate_374s4_S "锁定目标_纵坐标";
CM_ SG_ 884 Goal_Length_Relative_Spd_374s4_S "锁定目标_纵向相对速度";
CM_ SG_ 884 Goal_Late_Relative_Spd_374s4_S "锁定目标_横向相对速度";
CM_ SG_ 884 Target_State_B6_374s4_S "目标状态";
CM_ SG_ 884 Target_State_B1_374s4_S "目标状态";
CM_ SG_ 884 Target_Type_374s4_S "目标类型";
CM_ SG_ 884 AliveCounter_374s4_S "AliveCounter374";
CM_ SG_ 884 CheckSum_374s4_S "CheckSum374";
CM_ BO_ 843 "车道线目标";
CM_ SG_ 843 Left_Lane_Line_Type_S "左侧车道线类型";
CM_ SG_ 843 Right_Lane_Line_Type_S "右侧车道线类型";
CM_ SG_ 843 Left_Lane_Line_Y_Distance_S "左侧车道线Y向距离";
CM_ SG_ 843 Right_Lane_Line_Y_Distance_S "右侧车道线Y向距离";
CM_ SG_ 843 Lane_Line_Curvature_S "车道线曲率";
CM_ SG_ 843 AliveCounter_34B_S "AliveCounter_34B";
CM_ SG_ 843 CheckSum_34B_S "CheckSum_34B";
CM_ SG_ 813 MRR_Modulation_Status_S "前雷达调试状态";
CM_ SG_ 813 Front_Radar_FCTB_Warning_S "前雷达TCTB报警信号";
CM_ SG_ 813 Set_Speed_S "vSetDis 设置车速";
CM_ SG_ 813 Obj_Valid_S "ObjValid 探测有效目标";
CM_ SG_ 813 Tau_Gap_Set_S "TauGapSet 时间设置";
CM_ SG_ 813 Dx_Tar_Obj_S "dxTarObj 车距设置";
CM_ SG_ 813 PCW_Pre_Warning_S "PCW_preWarning PCW预报警信号";
CM_ SG_ 813 PCW_Latent_Warning_S "PCW_latentWarning PCW报警信号";
CM_ SG_ 813 PCW_State_S "PCW state  PCW状态";
CM_ SG_ 813 ACC_Mode_Display_S "ACCMode display ACC模式";
CM_ SG_ 813 ACC_State_S "ACC state ACC状态 ";
CM_ SG_ 813 Take_Over_Req_S "TakeOverReq 驾驶员接管请求";
CM_ SG_ 813 Speed_Unit_Set_S "Speed unit set 车速单位设置";
CM_ SG_ 813 CCR_AEB_Error_S "CCR AEB error";
CM_ SG_ 813 ACC_Text_Info_For_Driver_S "ACC_TextInfoForDriver";
CM_ SG_ 813 CCR_FCW_Error_S "CCR FCW error";
CM_ SG_ 813 Pedestrian_FCW_Brak_Error_S "Pedestrian FCW/braking error";
CM_ SG_ 813 Acute_Warning_S "Acute_warning";
CM_ SG_ 813 AEB_State_S "AEB state";
CM_ SG_ 813 PCW_Level_Feedback_S " PCW状态PCWLevelState";
CM_ SG_ 813 ACC_Mode_Display1_S "ACC模式1";
CM_ SG_ 813 Alive_Counter32D_S "AliveCounter32D";
CM_ SG_ 813 Checksum32D_S "CheckSum32D";
CM_ SG_ 814 ACC_Axv_Cv_Aim_S "ACC目标加速度 axvCvAim";
CM_ SG_ 814 Axv_Cv_Coft_Band_Upper_Val_S "加速度上限值 axvCvComfortBandUpperValue";
CM_ SG_ 814 Axv_Cv_Coft_Band_Lower_Val_S "加速度下限值axvCvComfortBandLowerValue";
CM_ SG_ 814 ADt_Upper_Limit_Axv_Cv_S "最大允许目标加速度变化率aDtUpperLimitAxvCv";
CM_ SG_ 814 ADt_Low_Limit_Axv_Cv_S "最小允许目标加速度变化率 aDtLowerLimitAxvCv";
CM_ SG_ 814 ACC_Drive_Off_Req_S "ACC驶离请求 ACC_DriveOffReq";
CM_ SG_ 814 ACC_DecTo_Stop_Req_S "ACC停车请求 ACC_DecToStopReq";
CM_ SG_ 814 ACC_Minimum_Braking_S "ACC最小制动请求ACC_Minimum_Braking";
CM_ SG_ 814 Brake_Preferred_S "预制动请求 BrakePreferred";
CM_ SG_ 814 ACC_Mode_S "ACCMode ACC模式";
CM_ SG_ 814 ESP_VLC_Shut_Down_Request_S "ESP_VLC模式关闭请求 ShutdownMode";
CM_ SG_ 814 Alive_Counter32E_S "AliveCounter32E";
CM_ SG_ 814 Checksum32E_S "CheckSum32E";
CM_ SG_ 815 MRR_MRC_Request_S "MRR MRC 请求状态";
CM_ SG_ 815 MRR_SOS_Request_S "SOS 请求状态";
CM_ SG_ 815 SeatbeltControl_Request_S "MRR安全带控制请求";
CM_ SG_ 815 ELK_OT_status_S "ELK overtaking status";
CM_ SG_ 815 ABA_Level_S "自适应制动辅助等级 ABAlevel";
CM_ SG_ 815 ABA_Available_S "自适应制动辅助有效位 ABARequest";
CM_ SG_ 815 AEB_Ax_Tar_S "AEB目标加速度
AEBaxTar";
CM_ SG_ 815 Req_EBA_Decel_Ctrl_S "EBA减速控制需求
Request of EBA deceleration control";
CM_ SG_ 815 ESP_Prefill_Req_S "ESP预填充请求 Prefill";
CM_ SG_ 815 AWB_Request_S "AWB请求 AWBRequest";
CM_ SG_ 815 AEB_DecCtrl_Request_S "AEB减速请求 AEBDecCtrlRequest";
CM_ SG_ 815 AWB_Level_S "AWB等级 AWBlevel";
CM_ SG_ 815 Req_ESC_Ctrl_Veh_S "请求ESC控制车辆 Request the ESC to hold the vehicle";
CM_ SG_ 815 ISLC_Sts_S "智能限速控制功能状态";
CM_ SG_ 815 ELK_status_S "ELK status";
CM_ SG_ 815 ISLC_Warnning_S "智能限速功能提醒";
CM_ SG_ 815 ELK_Take_Over_Req_S "横向驾驶员接管请求";
CM_ SG_ 815 Alive_Counter32F_S "AliveCounter32F";
CM_ SG_ 815 Checksum32F_S "CheckSum32F";
BA_DEF_ BO_  "CANFD_BRS" ENUM  "0","1";
BA_DEF_ BO_  "VFrameFormat" ENUM  "StandardCAN","ExtendedCAN","reserved","reserved","reserved","reserved","reserved","reserved","reserved","reserved","reserved","reserved","reserved","reserved","StandardCAN_FD","ExtendedCAN_FD";
BA_DEF_ BO_  "GenMsgSendType" ENUM  "Cycle","Event","CE","NoSendType","IfActive";
BA_DEF_ BO_  "GenMsgCycleTime" INT 0 1000;
BA_DEF_ BO_  "GenMsgCycleTimeFast" INT 0 1000;
BA_DEF_ SG_  "GenSigStartValue" HEX 0 4294967295;
BA_DEF_ SG_  "GenSigInvalidValue" HEX 0 4294967295;
BA_DEF_ SG_  "SignalPosition" STRING ;
BA_DEF_ SG_  "SignalValueDescription" STRING ;
BA_DEF_DEF_  "CANFD_BRS" "0";
BA_DEF_DEF_  "VFrameFormat" "StandardCAN";
BA_DEF_DEF_  "GenMsgSendType" "Cycle";
BA_DEF_DEF_  "GenMsgCycleTime" 1.56548806558447E-315;
BA_DEF_DEF_  "GenMsgCycleTimeFast" 0;
BA_DEF_DEF_  "GenSigStartValue" 0;
BA_DEF_DEF_  "GenSigInvalidValue" 0;
BA_DEF_DEF_  "SignalPosition" "";
BA_DEF_DEF_  "SignalValueDescription" "";
BA_ "CANFD_BRS" BO_ 289 1;
BA_ "GenMsgCycleTime" BO_ 289 20;
BA_ "VFrameFormat" BO_ 289 14;
BA_ "CANFD_BRS" BO_ 291 1;
BA_ "GenMsgCycleTime" BO_ 291 10;
BA_ "VFrameFormat" BO_ 291 14;
BA_ "CANFD_BRS" BO_ 546 1;
BA_ "GenMsgCycleTime" BO_ 546 20;
BA_ "VFrameFormat" BO_ 546 14;
BA_ "CANFD_BRS" BO_ 547 1;
BA_ "GenMsgCycleTime" BO_ 547 20;
BA_ "VFrameFormat" BO_ 547 14;
BA_ "CANFD_BRS" BO_ 544 1;
BA_ "GenMsgCycleTime" BO_ 544 20;
BA_ "VFrameFormat" BO_ 544 14;
BA_ "CANFD_BRS" BO_ 1058 1;
BA_ "GenMsgCycleTime" BO_ 1058 20;
BA_ "VFrameFormat" BO_ 1058 14;
BA_ "CANFD_BRS" BO_ 496 1;
BA_ "GenMsgCycleTime" BO_ 496 20;
BA_ "VFrameFormat" BO_ 496 14;
BA_ "CANFD_BRS" BO_ 213 1;
BA_ "GenMsgCycleTime" BO_ 213 10;
BA_ "VFrameFormat" BO_ 213 14;
BA_ "GenMsgCycleTime" BO_ 588 1000;
BA_ "VFrameFormat" BO_ 588 14;
BA_ "CANFD_BRS" BO_ 287 1;
BA_ "GenMsgCycleTime" BO_ 287 10;
BA_ "VFrameFormat" BO_ 287 14;
BA_ "CANFD_BRS" BO_ 792 1;
BA_ "GenMsgCycleTime" BO_ 792 20;
BA_ "VFrameFormat" BO_ 792 14;
BA_ "CANFD_BRS" BO_ 790 1;
BA_ "GenMsgCycleTime" BO_ 790 20;
BA_ "VFrameFormat" BO_ 790 14;
BA_ "CANFD_BRS" BO_ 1074 1;
BA_ "GenMsgCycleTime" BO_ 1074 1000;
BA_ "VFrameFormat" BO_ 1074 14;
BA_ "CANFD_BRS" BO_ 884 1;
BA_ "GenMsgCycleTime" BO_ 884 50;
BA_ "VFrameFormat" BO_ 884 14;
BA_ "CANFD_BRS" BO_ 843 1;
BA_ "GenMsgCycleTime" BO_ 843 50;
BA_ "VFrameFormat" BO_ 843 14;
BA_ "CANFD_BRS" BO_ 813 1;
BA_ "GenMsgCycleTime" BO_ 813 20;
BA_ "VFrameFormat" BO_ 813 14;
BA_ "CANFD_BRS" BO_ 814 1;
BA_ "GenMsgCycleTime" BO_ 814 20;
BA_ "VFrameFormat" BO_ 814 14;
BA_ "CANFD_BRS" BO_ 815 1;
BA_ "GenMsgCycleTime" BO_ 815 20;
BA_ "VFrameFormat" BO_ 815 14;
BA_ "GenSigInvalidValue" SG_ 289 IPB_Vehicle_Speed_S 4095;
BA_ "SignalValueDescription" SG_ 289 IPB_Vehicle_Speed_S "PH=INT*0.06875km/h

[0，281.4625]km/h

[0x000，0xFFE]

Invalid/Default：0xFFF

Initial：0x000";
BA_ "SignalPosition" SG_ 289 IPB_Vehicle_Speed_S "1.0-2.3";
BA_ "GenSigInvalidValue" SG_ 289 Vehicle_Speed_Stats_S 1;
BA_ "SignalValueDescription" SG_ 289 Vehicle_Speed_Stats_S "0x0：Valid

0x1：Invalid

Initial：0x0/Default：0x1";
BA_ "SignalPosition" SG_ 289 Vehicle_Speed_Stats_S "2.7";
BA_ "GenSigInvalidValue" SG_ 289 AWB_Available_S 15;
BA_ "SignalValueDescription" SG_ 289 AWB_Available_S "0x0：Not Available

0x1：Available";
BA_ "SignalPosition" SG_ 289 AWB_Available_S "4.4";
BA_ "GenSigInvalidValue" SG_ 289 AWB_Active_Brake_Warning_S 15;
BA_ "SignalValueDescription" SG_ 289 AWB_Active_Brake_Warning_S "0x0：No Active

0x1：Active";
BA_ "SignalPosition" SG_ 289 AWB_Active_Brake_Warning_S "4.5";
BA_ "GenSigInvalidValue" SG_ 289 AEB_Dec_Active_S 15;
BA_ "SignalValueDescription" SG_ 289 AEB_Dec_Active_S "0x0：No Active

0x1：Active";
BA_ "SignalPosition" SG_ 289 AEB_Dec_Active_S "4.6";
BA_ "GenSigInvalidValue" SG_ 289 AEB_not_Available_S 15;
BA_ "SignalValueDescription" SG_ 289 AEB_not_Available_S "0x0：Not Available

0x1：Available";
BA_ "SignalPosition" SG_ 289 AEB_not_Available_S "4.7";
BA_ "GenSigInvalidValue" SG_ 289 Prefill_Available_S 15;
BA_ "SignalValueDescription" SG_ 289 Prefill_Available_S "0x0：Not Available

0x1：Available";
BA_ "SignalPosition" SG_ 289 Prefill_Available_S "5.0";
BA_ "GenSigInvalidValue" SG_ 289 Prefill_Active_S 15;
BA_ "SignalValueDescription" SG_ 289 Prefill_Active_S "0x0：No Active

0x1：Active";
BA_ "SignalPosition" SG_ 289 Prefill_Active_S "5.1";
BA_ "GenSigInvalidValue" SG_ 289 ABAavailable_S 15;
BA_ "SignalValueDescription" SG_ 289 ABAavailable_S "0x0：Not Available

0x1：Available";
BA_ "SignalPosition" SG_ 289 ABAavailable_S "5.2";
BA_ "GenSigInvalidValue" SG_ 289 ABA_Active_S 15;
BA_ "SignalValueDescription" SG_ 289 ABA_Active_S "0x0：No Active

0x1：Active";
BA_ "SignalPosition" SG_ 289 ABA_Active_S "5.3";
BA_ "GenSigInvalidValue" SG_ 289 Alive_Counter_121_S 15;
BA_ "SignalValueDescription" SG_ 289 Alive_Counter_121_S "PH=INT*1

PH∈[0，15]";
BA_ "SignalPosition" SG_ 289 Alive_Counter_121_S "7.0-7.3";
BA_ "GenSigInvalidValue" SG_ 289 Checknum121_S 15;
BA_ "SignalValueDescription" SG_ 289 Checknum121_S "Checksum=(Byte1+Byte2?+Byte7)XOR0xFF";
BA_ "SignalPosition" SG_ 289 Checknum121_S "8.0-8.7";
BA_ "GenSigInvalidValue" SG_ 291 HHC_Fault_S 1;
BA_ "GenSigStartValue" SG_ 291 HHC_Fault_S 1;
BA_ "SignalValueDescription" SG_ 291 HHC_Fault_S "0x0：No Failure

0x1：Failure

Initial/Default：0x1";
BA_ "SignalPosition" SG_ 291 HHC_Fault_S "1.0";
BA_ "GenSigInvalidValue" SG_ 291 ATS_Ctrl_Status_S 1;
BA_ "GenSigStartValue" SG_ 291 ATS_Ctrl_Status_S 1;
BA_ "SignalValueDescription" SG_ 291 ATS_Ctrl_Status_S "0x0：ATSValid

0x1：ATSinValid";
BA_ "SignalPosition" SG_ 291 ATS_Ctrl_Status_S "1.1";
BA_ "SignalValueDescription" SG_ 291 Brake_Fluid_Warning_S "0x0：BrakeFluid_Normal

0x1：BrakeFluid_Empty

0x2：BrakeFluid_Electric_error

0x3：Reserved

Initial/Default：0x0";
BA_ "SignalPosition" SG_ 291 Brake_Fluid_Warning_S "1.2-1.3";
BA_ "SignalValueDescription" SG_ 291 IPB_Sport_Model_S "0x0：Inactive  

0x1：Active  

Initial/Default：0x0";
BA_ "SignalPosition" SG_ 291 IPB_Sport_Model_S "1.4";
BA_ "GenSigInvalidValue" SG_ 291 IPB_Func_Mode_S 3;
BA_ "GenSigStartValue" SG_ 291 IPB_Func_Mode_S 3;
BA_ "SignalValueDescription" SG_ 291 IPB_Func_Mode_S "0x0：舒适

0x1：标准

0x2-0x3：预留

Initial/Default：0x3";
BA_ "SignalPosition" SG_ 291 IPB_Func_Mode_S "1.5-1.6";
BA_ "GenSigInvalidValue" SG_ 291 Mmot_Tar_Fast_FA_S 255;
BA_ "GenSigStartValue" SG_ 291 Mmot_Tar_Fast_FA_S 255;
BA_ "SignalValueDescription" SG_ 291 Mmot_Tar_Fast_FA_S "PH=INT*0.392

INT∈[0x00，0xFE]

PH∈[0，99.6]%

Invalid：0xFF

Initial/Default：0xFF

";
BA_ "SignalPosition" SG_ 291 Mmot_Tar_Fast_FA_S "2.0-2.7";
BA_ "GenSigInvalidValue" SG_ 291 Mmot_Tar_Slow_S 255;
BA_ "GenSigStartValue" SG_ 291 Mmot_Tar_Slow_S 255;
BA_ "SignalValueDescription" SG_ 291 Mmot_Tar_Slow_S "PH=INT*0.392

INT∈[0x00，0xFE]

PH∈[0，99.6]%

Invalid：0xFF

Initial/Default：0xFF

";
BA_ "SignalPosition" SG_ 291 Mmot_Tar_Slow_S "3.0-3.7";
BA_ "SignalValueDescription" SG_ 291 HDC_Failure_S "0x0：No Failure

0x1：Failure

Initial/Default：0x0";
BA_ "SignalPosition" SG_ 291 HDC_Failure_S "6.0";
BA_ "SignalValueDescription" SG_ 291 HDC_CtrlStatus_S "0x0：HDCOff(nolamp)

0x1：HDCOnwithoutactivebraking(lampon)

0x2：HDCOnwithactivebraking(lampflashing)

0x3：IPBwithoutHDC

Initial/Default：0x0";
BA_ "SignalPosition" SG_ 291 HDC_CtrlStatus_S "6.1-6.2";
BA_ "SignalValueDescription" SG_ 291 Brake_Pedal_Status_S "0x0：Not Pressed

0x1：Pressed

0x2：Reserved

0x3：Error

Initial/Default：0x0";
BA_ "SignalPosition" SG_ 291 Brake_Pedal_Status_S "6.3-6.4";
BA_ "SignalValueDescription" SG_ 291 Basc_Front_S "0x0：Inactive

0x1：Active

Initial/Default：0x0";
BA_ "SignalPosition" SG_ 291 Basc_Front_S "6.5";
BA_ "SignalValueDescription" SG_ 291 Clutch_Pedal_Status_S "0x0：Not Pressed

0x1：Pressed

Initial/Default：0x0";
BA_ "SignalPosition" SG_ 291 Clutch_Pedal_Status_S "6.6";
BA_ "GenSigInvalidValue" SG_ 291 ACMH_Fault_S 1;
BA_ "GenSigStartValue" SG_ 291 ACMH_Fault_S 1;
BA_ "SignalValueDescription" SG_ 291 ACMH_Fault_S "0x0：No Failure

0x1：Failure

Initial/Default：0x1";
BA_ "SignalPosition" SG_ 291 ACMH_Fault_S "6.7";
BA_ "SignalValueDescription" SG_ 291 Counter123_S "PH=INT*1

PH∈[0，15]";
BA_ "SignalPosition" SG_ 291 Counter123_S "7.0-7.3";
BA_ "GenSigStartValue" SG_ 291 ESP_OFF_S 1;
BA_ "SignalValueDescription" SG_ 291 ESP_OFF_S "0x0：ESP ON

0x1：ESP OFF

Initial：0x1/Default：0x0";
BA_ "SignalPosition" SG_ 291 ESP_OFF_S "7.4";
BA_ "SignalValueDescription" SG_ 291 ESP_Active_S "0x0：No Active

0x1：Active

Initial/Default：0x0";
BA_ "SignalPosition" SG_ 291 ESP_Active_S "7.5";
BA_ "GenSigInvalidValue" SG_ 291 TCS_Fault_S 1;
BA_ "GenSigStartValue" SG_ 291 TCS_Fault_S 1;
BA_ "SignalValueDescription" SG_ 291 TCS_Fault_S "0x0：No Failure

0x1：Failure

Initial/Default：0x1";
BA_ "SignalPosition" SG_ 291 TCS_Fault_S "7.6";
BA_ "GenSigInvalidValue" SG_ 291 VDC_Fault_S 1;
BA_ "GenSigStartValue" SG_ 291 VDC_Fault_S 1;
BA_ "SignalValueDescription" SG_ 291 VDC_Fault_S "0x0：No Failure

0x1：Failure

Initial/Default：0x1";
BA_ "SignalPosition" SG_ 291 VDC_Fault_S "7.7";
BA_ "SignalValueDescription" SG_ 291 Checksum123_S "Checksum = (Byte1+Byte2…+ Byte7) XOR 0xFF";
BA_ "SignalPosition" SG_ 291 Checksum123_S "8.0-8.7";
BA_ "GenSigInvalidValue" SG_ 546 Yaw_Rate_Signal_S 15;
BA_ "SignalValueDescription" SG_ 546 Yaw_Rate_Signal_S "PH：[-2.0943rad/s，+2.0943rad/s]

PH=INT*0.002132603-2.0943[rad/s]

Resolution：0.002132603[rad/s]

Initial：0[rad/s]

Invalid：FFFh";
BA_ "SignalPosition" SG_ 546 Yaw_Rate_Signal_S "1.0-2.3";
BA_ "GenSigInvalidValue" SG_ 546 Yaw_Rate_Offset_S 15;
BA_ "SignalValueDescription" SG_ 546 Yaw_Rate_Offset_S "PH：[-0.13rad/s，+0.13rad/s]

PH=INT*0.002132603-0.13[rad/s]

Resolution：0.002132603[rad/s]

Initial：0[rad/s]

Invalid：FFFh";
BA_ "SignalPosition" SG_ 546 Yaw_Rate_Offset_S "2.4-3.7";
BA_ "GenSigInvalidValue" SG_ 546 EBD_Active_222_S 15;
BA_ "SignalValueDescription" SG_ 546 EBD_Active_222_S "0x0：No Active

0x1：Active

Initial/Default：0x0";
BA_ "SignalPosition" SG_ 546 EBD_Active_222_S "4.0";
BA_ "GenSigInvalidValue" SG_ 546 ABS_Active_222_S 15;
BA_ "SignalValueDescription" SG_ 546 ABS_Active_222_S "0x0：No Active

0x1：Active

Initial/Default：0x0";
BA_ "SignalPosition" SG_ 546 ABS_Active_222_S "4.1";
BA_ "GenSigInvalidValue" SG_ 546 EBD_Fault_222_S 15;
BA_ "SignalValueDescription" SG_ 546 EBD_Fault_222_S "0x0：No Failure

0x1：Failure

Initial/Default：0x1";
BA_ "SignalPosition" SG_ 546 EBD_Fault_222_S "4.2";
BA_ "GenSigInvalidValue" SG_ 546 ABS_Fault_222_S 15;
BA_ "SignalValueDescription" SG_ 546 ABS_Fault_222_S "0x0：No Failure

0x1：Failure

Initial/Default：0x1";
BA_ "SignalPosition" SG_ 546 ABS_Fault_222_S "4.3";
BA_ "GenSigInvalidValue" SG_ 546 TCS_Active_222_S 15;
BA_ "SignalValueDescription" SG_ 546 TCS_Active_222_S "0x0：Not Active

0x1：Active";
BA_ "SignalPosition" SG_ 546 TCS_Active_222_S "4.4";
BA_ "GenSigInvalidValue" SG_ 546 DWT_B_Active_222_S 15;
BA_ "SignalValueDescription" SG_ 546 DWT_B_Active_222_S "0x0：Not Active

0x1：Active";
BA_ "SignalPosition" SG_ 546 DWT_B_Active_222_S "4.5";
BA_ "GenSigInvalidValue" SG_ 546 VDC_Active_222_S 15;
BA_ "SignalValueDescription" SG_ 546 VDC_Active_222_S "0x0：Not Active

0x1：Active";
BA_ "SignalPosition" SG_ 546 VDC_Active_222_S "4.6";
BA_ "GenSigInvalidValue" SG_ 546 Yaw_Rate_Status_S 15;
BA_ "SignalValueDescription" SG_ 546 Yaw_Rate_Status_S "0x0：Not Valid

0x1：Valid";
BA_ "SignalPosition" SG_ 546 Yaw_Rate_Status_S "4.7";
BA_ "GenSigInvalidValue" SG_ 546 Message_Counter222_S 15;
BA_ "SignalValueDescription" SG_ 546 Message_Counter222_S "PH=INT*1

PH∈[0，15]";
BA_ "SignalPosition" SG_ 546 Message_Counter222_S "7.0-7.3";
BA_ "GenSigInvalidValue" SG_ 546 Checksum222_S 15;
BA_ "SignalValueDescription" SG_ 546 Checksum222_S "Checksum=(Byte1+Byte2+Byte3…+Byte7)XOR0xFF";
BA_ "SignalPosition" SG_ 546 Checksum222_S "8.0-8.7";
BA_ "GenSigInvalidValue" SG_ 547 IPB_AX_S 15;
BA_ "SignalValueDescription" SG_ 547 IPB_AX_S "PH：[-21.593m/s2，+21.593m/s2]

PH=INT*0.027126736-21.593m/s2]

Resolution：0.027126736[m/s2]

Initialisationvalue：0[m/s2]

Invalidvalue：7FFh";
BA_ "SignalPosition" SG_ 547 IPB_AX_S "1.0-2.3";
BA_ "GenSigInvalidValue" SG_ 547 IPB_AX_offset_S 15;
BA_ "SignalValueDescription" SG_ 547 IPB_AX_offset_S "PH：[-21.593m/s2，+21.593m/s2]

PH=INT*0.027126736-21.593m/s2]

Resolution：0.027126736[m/s2]

Initialisationvalue：0[m/s2]

Invalidvalue：7FFh";
BA_ "SignalPosition" SG_ 547 IPB_AX_offset_S "2.4-3.7";
BA_ "GenSigInvalidValue" SG_ 547 IPB_AY_S 15;
BA_ "SignalValueDescription" SG_ 547 IPB_AY_S "PH：[-21.593m/s2，+21.593m/s2]

PH=INT*0.027126736-21.593m/s2]

Resolution：0.027126736[m/s2]

Initialisationvalue：0[m/s2]

Invalidvalue：7FFh";
BA_ "SignalPosition" SG_ 547 IPB_AY_S "4.0-5.3";
BA_ "GenSigInvalidValue" SG_ 547 IPB_AY_Offset_S 15;
BA_ "SignalValueDescription" SG_ 547 IPB_AY_Offset_S "PH：[-21.593m/s2，+21.593m/s2]

PH=INT*0.027126736-21.593m/s2]

Resolution：0.027126736[m/s2]

Initialisationvalue：0[m/s2]

Invalidvalue：7FFh";
BA_ "SignalPosition" SG_ 547 IPB_AY_Offset_S "5.4-6.7";
BA_ "GenSigInvalidValue" SG_ 547 Message_Counter223_S 15;
BA_ "SignalValueDescription" SG_ 547 Message_Counter223_S "PH=INT*1

PH∈[0，15]";
BA_ "SignalPosition" SG_ 547 Message_Counter223_S "7.0-7.3";
BA_ "GenSigInvalidValue" SG_ 547 IPB_AY_Status_S 15;
BA_ "SignalValueDescription" SG_ 547 IPB_AY_Status_S "0x0：Not Valid

0x1：Valid";
BA_ "SignalPosition" SG_ 547 IPB_AY_Status_S "7.6";
BA_ "GenSigInvalidValue" SG_ 547 IPB_AX_Status_S 15;
BA_ "SignalValueDescription" SG_ 547 IPB_AX_Status_S "0x0：Not Valid

0x1：Valid";
BA_ "SignalPosition" SG_ 547 IPB_AX_Status_S "7.7";
BA_ "GenSigInvalidValue" SG_ 547 Checksum223_S 15;
BA_ "SignalValueDescription" SG_ 547 Checksum223_S "Checksum=(Byte1+Byte2+Byte3…+Byte7)XOR0xFF";
BA_ "SignalPosition" SG_ 547 Checksum223_S "8.0-8.7";
BA_ "GenSigInvalidValue" SG_ 544 RR_Wheel_Drive_Direction_S 15;
BA_ "SignalValueDescription" SG_ 544 RR_Wheel_Drive_Direction_S "0x0：Undefinable

0x1：Forward

0x2：Backward

0x3：Stop";
BA_ "SignalPosition" SG_ 544 RR_Wheel_Drive_Direction_S "1.0-1.1";
BA_ "GenSigInvalidValue" SG_ 544 RL_Wheel_Drive_Direction_S 15;
BA_ "SignalValueDescription" SG_ 544 RL_Wheel_Drive_Direction_S "0x0：Undefinable

0x1：Forward

0x2：Backward

0x3：Stop";
BA_ "SignalPosition" SG_ 544 RL_Wheel_Drive_Direction_S "1.2-1.3";
BA_ "GenSigInvalidValue" SG_ 544 FR_Wheel_Drive_Direction_S 15;
BA_ "SignalValueDescription" SG_ 544 FR_Wheel_Drive_Direction_S "0x0：Undefinable

0x1：Forward

0x2：Backward

0x3：Stop";
BA_ "SignalPosition" SG_ 544 FR_Wheel_Drive_Direction_S "1.4-1.5";
BA_ "GenSigInvalidValue" SG_ 544 FL_Wheel_Drive_Direction_S 15;
BA_ "SignalValueDescription" SG_ 544 FL_Wheel_Drive_Direction_S "0x0：Undefinable

0x1：Forward

0x2：Backward

0x3：Stop";
BA_ "SignalPosition" SG_ 544 FL_Wheel_Drive_Direction_S "1.6-1.7";
BA_ "GenSigInvalidValue" SG_ 544 Active_Vehicle_Hold_S 15;
BA_ "SignalValueDescription" SG_ 544 Active_Vehicle_Hold_S "0x0：Not Active Vehicle Hold

0x1：Active Vehicle Hold";
BA_ "SignalPosition" SG_ 544 Active_Vehicle_Hold_S "2.0";
BA_ "GenSigInvalidValue" SG_ 544 VLC_Available_S 15;
BA_ "SignalValueDescription" SG_ 544 VLC_Available_S "0x0：Not Available

0x1：Available";
BA_ "SignalPosition" SG_ 544 VLC_Available_S "2.1";
BA_ "GenSigInvalidValue" SG_ 544 VLC_Active_S 15;
BA_ "SignalValueDescription" SG_ 544 VLC_Active_S "0x0：No Active

0x1：Active";
BA_ "SignalPosition" SG_ 544 VLC_Active_S "2.2";
BA_ "GenSigInvalidValue" SG_ 544 VLC_Fail_S 15;
BA_ "SignalValueDescription" SG_ 544 VLC_Fail_S "0x0：No Failure

0x1：Failure";
BA_ "SignalPosition" SG_ 544 VLC_Fail_S "2.3";
BA_ "GenSigInvalidValue" SG_ 544 No_Brake_Force_S 15;
BA_ "SignalValueDescription" SG_ 544 No_Brake_Force_S "0x0：Exist Brake Force

0x1：No Brake Force";
BA_ "SignalPosition" SG_ 544 No_Brake_Force_S "2.4";
BA_ "GenSigInvalidValue" SG_ 544 IPB_Request_EPB_S 15;
BA_ "SignalValueDescription" SG_ 544 IPB_Request_EPB_S "0x0：IPBRequest Apb_NotInitialized

0x1：IPBRequestApb_NoRequest

0x2：IPBRequestApb_ReleaseBrake

0x3：IPBRequestApb_LockBrake";
BA_ "SignalPosition" SG_ 544 IPB_Request_EPB_S "2.5-2.6";
BA_ "GenSigInvalidValue" SG_ 544 QDC_ACC_S 15;
BA_ "SignalValueDescription" SG_ 544 QDC_ACC_S "0x0：No Error

0x1：Error";
BA_ "SignalPosition" SG_ 544 QDC_ACC_S "2.7";
BA_ "GenSigInvalidValue" SG_ 544 ECD_Temp_Off_S 15;
BA_ "SignalValueDescription" SG_ 544 ECD_Temp_Off_S "0x0：Not High

0x1：Temp Too High";
BA_ "SignalPosition" SG_ 544 ECD_Temp_Off_S "3";
BA_ "GenSigInvalidValue" SG_ 544 Vlc_Prevent_Fuel_Cut_Off_S 15;
BA_ "SignalValueDescription" SG_ 544 Vlc_Prevent_Fuel_Cut_Off_S "0x0：No Request To Prevent Fule Cutoff

0x1：Request To Prevent Fule Cutoff";
BA_ "SignalPosition" SG_ 544 Vlc_Prevent_Fuel_Cut_Off_S "3.1";
BA_ "GenSigInvalidValue" SG_ 544 Vehicle_Stand_Still_S 15;
BA_ "SignalValueDescription" SG_ 544 Vehicle_Stand_Still_S "0x0：Not Standstill

0x1：Standstill

0x2：Invalid(shortunavailability，max3s)

0x3：Reserved";
BA_ "SignalPosition" SG_ 544 Vehicle_Stand_Still_S "3.2-3.3";
BA_ "GenSigInvalidValue" SG_ 544 FL_Wheel_Drive_Direct_Stat_S 15;
BA_ "SignalValueDescription" SG_ 544 FL_Wheel_Drive_Direct_Stat_S "0x0：Valid

0x1：Invalid";
BA_ "SignalPosition" SG_ 544 FL_Wheel_Drive_Direct_Stat_S "3.4";
BA_ "GenSigInvalidValue" SG_ 544 FR_Wheel_Drive_Direct_Stat_S 15;
BA_ "SignalValueDescription" SG_ 544 FR_Wheel_Drive_Direct_Stat_S "0x0：Valid

0x1：Invalid";
BA_ "SignalPosition" SG_ 544 FR_Wheel_Drive_Direct_Stat_S "3.5";
BA_ "GenSigInvalidValue" SG_ 544 RL_Wheel_Drive_Direct_Stat_S 15;
BA_ "SignalValueDescription" SG_ 544 RL_Wheel_Drive_Direct_Stat_S "0x0：Valid

0x1：Invalid";
BA_ "SignalPosition" SG_ 544 RL_Wheel_Drive_Direct_Stat_S "3.6";
BA_ "GenSigInvalidValue" SG_ 544 RR_Wheel_Drive_Direct_Stat_S 15;
BA_ "SignalValueDescription" SG_ 544 RR_Wheel_Drive_Direct_Stat_S "0x0：Valid

0x1：Invalid";
BA_ "SignalPosition" SG_ 544 RR_Wheel_Drive_Direct_Stat_S "3.7";
BA_ "GenSigInvalidValue" SG_ 544 VLC_Internal_Targ_Accel_S 15;
BA_ "SignalValueDescription" SG_ 544 VLC_Internal_Targ_Accel_S "PH=INT*0.05-7[m/s2]

[0x00，0xFF]

[-7，5.75][m/s2]";
BA_ "SignalPosition" SG_ 544 VLC_Internal_Targ_Accel_S "4.0-4.7";
BA_ "GenSigInvalidValue" SG_ 544 VLC_Torque_Request_Value_S 15;
BA_ "SignalValueDescription" SG_ 544 VLC_Torque_Request_Value_S "PH=INT-12000

[-12000，12000]NM

[0x0000，0x5DC0]";
BA_ "SignalPosition" SG_ 544 VLC_Torque_Request_Value_S "5.0-6.7";
BA_ "GenSigInvalidValue" SG_ 544 Message_Counter220_S 15;
BA_ "SignalValueDescription" SG_ 544 Message_Counter220_S "PH=INT*1

PH∈[0，15]";
BA_ "SignalPosition" SG_ 544 Message_Counter220_S "7.0-7.3";
BA_ "GenSigInvalidValue" SG_ 544 VLC_Torque_Request_Status_S 15;
BA_ "SignalValueDescription" SG_ 544 VLC_Torque_Request_Status_S "0x0：No Active

0x1：Active";
BA_ "SignalPosition" SG_ 544 VLC_Torque_Request_Status_S "7.4";
BA_ "GenSigInvalidValue" SG_ 544 CDD_Available_S 15;
BA_ "SignalValueDescription" SG_ 544 CDD_Available_S "0x0：No Available

0x1：Available";
BA_ "SignalPosition" SG_ 544 CDD_Available_S "7.5";
BA_ "GenSigInvalidValue" SG_ 544 CDD_Active_S 15;
BA_ "SignalValueDescription" SG_ 544 CDD_Active_S "0x0：No Active

0x1：Active";
BA_ "SignalPosition" SG_ 544 CDD_Active_S "7.6";
BA_ "SignalValueDescription" SG_ 544 CDD_Fail_S "0x0：No Failure

0x1：Failure";
BA_ "SignalPosition" SG_ 544 CDD_Fail_S "7.7";
BA_ "SignalValueDescription" SG_ 544 CheckSum220_S "Checksum=(Byte1+Byte2…+Byte7)XOR0xFF";
BA_ "SignalPosition" SG_ 544 CheckSum220_S "8.0-8.7";
BA_ "GenSigInvalidValue" SG_ 1058 FL_Wheel_Pulse_Counter_422_S 15;
BA_ "SignalValueDescription" SG_ 1058 FL_Wheel_Pulse_Counter_422_S "PH=INT*1

PH∈[0，1022]

Initial：0x0

Invalid/Default：0x3FF";
BA_ "SignalPosition" SG_ 1058 FL_Wheel_Pulse_Counter_422_S "1.0-2.1";
BA_ "GenSigInvalidValue" SG_ 1058 RR_Wheel_Puls_Count_Valid_422_S 15;
BA_ "SignalValueDescription" SG_ 1058 RR_Wheel_Puls_Count_Valid_422_S "0x0：Valid

0x1：Invalid";
BA_ "SignalPosition" SG_ 1058 RR_Wheel_Puls_Count_Valid_422_S "2.4";
BA_ "GenSigInvalidValue" SG_ 1058 RL_Wheel_Puls_Count_Valid_422_S 15;
BA_ "SignalValueDescription" SG_ 1058 RL_Wheel_Puls_Count_Valid_422_S "0x0：Valid

0x1：Invalid";
BA_ "SignalPosition" SG_ 1058 RL_Wheel_Puls_Count_Valid_422_S "2.5";
BA_ "GenSigInvalidValue" SG_ 1058 FR_Wheel_Puls_Count_Valid_422_S 15;
BA_ "SignalValueDescription" SG_ 1058 FR_Wheel_Puls_Count_Valid_422_S "0x0：Valid

0x1：Invalid";
BA_ "SignalPosition" SG_ 1058 FR_Wheel_Puls_Count_Valid_422_S "2.6";
BA_ "GenSigInvalidValue" SG_ 1058 FL_Wheel_Puls_Count_Valid_422_S 15;
BA_ "SignalValueDescription" SG_ 1058 FL_Wheel_Puls_Count_Valid_422_S "0x0：Valid

0x1：Invalid";
BA_ "SignalPosition" SG_ 1058 FL_Wheel_Puls_Count_Valid_422_S "2.7";
BA_ "GenSigInvalidValue" SG_ 1058 FR_Wheel_Pulse_Counter_422_S 15;
BA_ "SignalValueDescription" SG_ 1058 FR_Wheel_Pulse_Counter_422_S "PH=INT*1

PH∈[0，1022]

Initial：0x0

Invalid/Default：0x3FF";
BA_ "SignalPosition" SG_ 1058 FR_Wheel_Pulse_Counter_422_S "3.0-4.1";
BA_ "GenSigInvalidValue" SG_ 1058 RL_Wheel_Pulse_Counter_422_S 15;
BA_ "SignalValueDescription" SG_ 1058 RL_Wheel_Pulse_Counter_422_S "PH=INT*1

PH∈[0，1022]

Initial：0x0

Invalid/Default：0x3FF";
BA_ "SignalPosition" SG_ 1058 RL_Wheel_Pulse_Counter_422_S "4.4-5.5";
BA_ "GenSigInvalidValue" SG_ 1058 RR_Wheel_Pulse_Counter_422_S 15;
BA_ "SignalValueDescription" SG_ 1058 RR_Wheel_Pulse_Counter_422_S "PH=INT*1

PH∈[0，1022]

Initial：0x0

Invalid/Default：0x3FF";
BA_ "SignalPosition" SG_ 1058 RR_Wheel_Pulse_Counter_422_S "6.0-7.1";
BA_ "GenSigInvalidValue" SG_ 1058 Message_Counter422_S 15;
BA_ "SignalValueDescription" SG_ 1058 Message_Counter422_S "PH=INT*1

PH∈[0，15]";
BA_ "SignalPosition" SG_ 1058 Message_Counter422_S "7.4-7.7";
BA_ "GenSigInvalidValue" SG_ 1058 CheckSum422_S 15;
BA_ "SignalValueDescription" SG_ 1058 CheckSum422_S "Checksum=(Byte1+Byte2…+Byte7)XOR0xFF";
BA_ "SignalPosition" SG_ 1058 CheckSum422_S "8.0-8.7";
BA_ "GenSigInvalidValue" SG_ 496 Wheel_Speed_FL_1F0_S 15;
BA_ "SignalValueDescription" SG_ 496 Wheel_Speed_FL_1F0_S "PH=INT*0.06875km/h

[0，281.4625]km/h

[0x000，0xFFE]

Invalid/Default：0xFFF

Initial：0x000";
BA_ "SignalPosition" SG_ 496 Wheel_Speed_FL_1F0_S "1.0-2.3";
BA_ "GenSigInvalidValue" SG_ 496 Wheel_Speed_FR_Stats_1F0_S 15;
BA_ "SignalValueDescription" SG_ 496 Wheel_Speed_FR_Stats_1F0_S "0x0：Valid

0x1：Invalid";
BA_ "SignalPosition" SG_ 496 Wheel_Speed_FR_Stats_1F0_S "2.4";
BA_ "GenSigInvalidValue" SG_ 496 Wheel_Speed_FL_Stats_1F0_S 15;
BA_ "SignalValueDescription" SG_ 496 Wheel_Speed_FL_Stats_1F0_S "0x0：Valid

0x1：Invalid";
BA_ "SignalPosition" SG_ 496 Wheel_Speed_FL_Stats_1F0_S "2.5";
BA_ "GenSigInvalidValue" SG_ 496 Wheel_Speed_RR_Stats_1F0_S 15;
BA_ "SignalValueDescription" SG_ 496 Wheel_Speed_RR_Stats_1F0_S "0x0：Valid

0x1：Invalid";
BA_ "SignalPosition" SG_ 496 Wheel_Speed_RR_Stats_1F0_S "2.6";
BA_ "GenSigInvalidValue" SG_ 496 WheelSpeed_RL_Status_1F0_S 15;
BA_ "SignalValueDescription" SG_ 496 WheelSpeed_RL_Status_1F0_S "0x0：Valid

0x1：Invalid";
BA_ "SignalPosition" SG_ 496 WheelSpeed_RL_Status_1F0_S "2.7";
BA_ "GenSigInvalidValue" SG_ 496 Wheel_Speed_FR_1F0_S 15;
BA_ "SignalValueDescription" SG_ 496 Wheel_Speed_FR_1F0_S "PH=INT*0.06875km/h

[0，281.4625]km/h

[0x000，0xFFE]

Invalid：0xFFF

Initial：0x000/Default：0xFFF";
BA_ "SignalPosition" SG_ 496 Wheel_Speed_FR_1F0_S "3.0-4.3";
BA_ "GenSigInvalidValue" SG_ 496 Wheel_Speed_RL_1F0_S 15;
BA_ "SignalValueDescription" SG_ 496 Wheel_Speed_RL_1F0_S "PH=INT*0.06875km/h

[0，281.4625]km/h

[0x000，0xFFE]

Invalid：0xFFF

Initial：0x000/Default：0xFFF";
BA_ "SignalPosition" SG_ 496 Wheel_Speed_RL_1F0_S "4.4-5.7";
BA_ "GenSigInvalidValue" SG_ 496 Wheel_Speed_RR_1F0_S 15;
BA_ "SignalValueDescription" SG_ 496 Wheel_Speed_RR_1F0_S "PH=INT*0.06875km/h

[0，281.4625]km/h

[0x000，0xFFE]

Invalid：0xFFF

Initial：0x000/Default：0xFFF";
BA_ "SignalPosition" SG_ 496 Wheel_Speed_RR_1F0_S "6.0-7.3";
BA_ "GenSigInvalidValue" SG_ 496 Message_Counter_1F0_S 15;
BA_ "SignalValueDescription" SG_ 496 Message_Counter_1F0_S "PH=INT*1

PH∈[0，15]";
BA_ "SignalPosition" SG_ 496 Message_Counter_1F0_S "7.4-7.7";
BA_ "GenSigInvalidValue" SG_ 496 Checksum_1F0_S 15;
BA_ "SignalValueDescription" SG_ 496 Checksum_1F0_S "Checksum=(Byte1+Byte2?+Byte7)XOR0xFF";
BA_ "SignalPosition" SG_ 496 Checksum_1F0_S "8.0-8.7";
BA_ "GenSigInvalidValue" SG_ 213 IPB_Imput_Rod_Stroke_S 15;
BA_ "SignalValueDescription" SG_ 213 IPB_Imput_Rod_Stroke_S "PH=INT*0.05-5

[-5，46.15]mm

[0x000，0x3FE]

Initial：0x064";
BA_ "SignalPosition" SG_ 213 IPB_Imput_Rod_Stroke_S "1.0-2.1";
BA_ "GenSigInvalidValue" SG_ 213 IPB_Imput_Rod_Stroke_State_S 15;
BA_ "SignalValueDescription" SG_ 213 IPB_Imput_Rod_Stroke_State_S "0x0：Valid

0x1：Invalid";
BA_ "SignalPosition" SG_ 213 IPB_Imput_Rod_Stroke_State_S "2.2";
BA_ "GenSigInvalidValue" SG_ 213 Message_Counter0D5_S 15;
BA_ "SignalValueDescription" SG_ 213 Message_Counter0D5_S "PH=INT*1

PH∈[0，15]";
BA_ "SignalPosition" SG_ 213 Message_Counter0D5_S "7.4-7.7";
BA_ "GenSigInvalidValue" SG_ 213 CheckSum_0D5_S 15;
BA_ "SignalValueDescription" SG_ 213 CheckSum_0D5_S "Checksum=(Byte1+Byte2…+Byte7)XOR0xFF";
BA_ "SignalPosition" SG_ 213 CheckSum_0D5_S "8.0-8.7";
BA_ "GenSigStartValue" SG_ 588 Steering_Mode_Status_S 1;
BA_ "SignalValueDescription" SG_ 588 Steering_Mode_Status_S "0x0：无效

0x1：舒适

0x2：舒适+

0x3：运动

0x4：运动+

0x5:车道保持模式

0x6-0xF：预留";
BA_ "SignalPosition" SG_ 588 Steering_Mode_Status_S "2.0-2.2";
BA_ "SignalValueDescription" SG_ 588 Counter_24C_S "PH=INT*1";
BA_ "SignalPosition" SG_ 588 Counter_24C_S "7.4-7.7";
BA_ "SignalValueDescription" SG_ 588 CheckSum24C_S "Checksum=(Byte1+byte2…+Byte7)XOR0xFF";
BA_ "SignalPosition" SG_ 588 CheckSum24C_S "8.0-8.7";
BA_ "GenSigInvalidValue" SG_ 287 Steering_Wheel_Angle_S 32767;
BA_ "SignalValueDescription" SG_ 287 Steering_Wheel_Angle_S "PhysicalRange

[-780.0°，+779.9°]

Normalization：

[E188h，1E77h]

Resolution：0.1°/bit

Fault：7FFFh

Default：0°";
BA_ "SignalPosition" SG_ 287 Steering_Wheel_Angle_S "1.0-2.7";
BA_ "GenSigInvalidValue" SG_ 287 Steering_Wheel_Rotation_Speed_S 255;
BA_ "SignalValueDescription" SG_ 287 Steering_Wheel_Rotation_Speed_S "PH=INT*4°/s

[0x00，0xFE]

[0，1016]°/s

Fault：0xFF

Default：0°/s";
BA_ "SignalPosition" SG_ 287 Steering_Wheel_Rotation_Speed_S "3.0-3.7";
BA_ "SignalValueDescription" SG_ 287 Failure_Stats_OK_S "0x0：Sensor Information Invalid

0x1：Sensor Information Valid";
BA_ "SignalPosition" SG_ 287 Failure_Stats_OK_S "4.0";
BA_ "GenSigInvalidValue" SG_ 287 Sensor_Calibration_Stats_S 1;
BA_ "GenSigStartValue" SG_ 287 Sensor_Calibration_Stats_S 1;
BA_ "SignalValueDescription" SG_ 287 Sensor_Calibration_Stats_S "0x0：Sensor Not Calibrated

0x1：Sensor1 Calibrated";
BA_ "SignalPosition" SG_ 287 Sensor_Calibration_Stats_S "4.1";
BA_ "GenSigInvalidValue" SG_ 287 TRIM_Trimming_Stats_S 1;
BA_ "GenSigStartValue" SG_ 287 TRIM_Trimming_Stats_S 1;
BA_ "SignalValueDescription" SG_ 287 TRIM_Trimming_Stats_S "0x0：Sensor Not Trimmed

0x1：Sensor Trimmed";
BA_ "SignalPosition" SG_ 287 TRIM_Trimming_Stats_S "4.2";
BA_ "SignalValueDescription" SG_ 287 SF1_5_Internal_Stats_S "PH=INT*1

[0，31]";
BA_ "SignalPosition" SG_ 287 SF1_5_Internal_Stats_S "4.3-4.7";
BA_ "SignalValueDescription" SG_ 287 SAS_Scroll_Cycle_11F_Cnt_S "PH=INT*1

[0，15]";
BA_ "SignalPosition" SG_ 287 SAS_Scroll_Cycle_11F_Cnt_S "5.0-5.3";
BA_ "SignalValueDescription" SG_ 287 SAS_Checksum11F_S "[0，15]";
BA_ "SignalPosition" SG_ 287 SAS_Checksum11F_S "5.4-5.7";
BA_ "SignalValueDescription" SG_ 792 EPS_LKA_Control_State_S "0x0：EPSExternalSteeringTorqueRequireControlNotReady

0x1：EPSExternalSteeringTorqueRequireControlReady

0x2：EPSExternalSteeringTorqueRequireControlActive

0x3：ExternalRequireorEPSTemporaryFailed

0x4：ExternalRequireorEPSPermanentlyFailed

0x5-0x7：Re";
BA_ "SignalPosition" SG_ 792 EPS_LKA_Control_State_S "1.0-1.2";
BA_ "SignalValueDescription" SG_ 792 LKA_Control_Delivered_Value_S "PH=INT*0.01Nm

INT∈[0xE0C，0x1F4]

PH∈[-5，5]Nm

Resolution：0.01Nm

Left：Positive

Right：Negative";
BA_ "SignalPosition" SG_ 792 LKA_Control_Delivered_Value_S "2.0-3.3";
BA_ "SignalValueDescription" SG_ 792 LKACtrlDlvdValue_VD_S "0x0：Invalid

0x1：Valid";
BA_ "SignalPosition" SG_ 792 LKACtrlDlvdValue_VD_S "3.4";
BA_ "SignalValueDescription" SG_ 792 Hnads_Off_Detected_States_S "0x0：Hands Off Not Detected

0x1：Hands Of Detected";
BA_ "SignalPosition" SG_ 792 Hnads_Off_Detected_States_S "3.5";
BA_ "SignalValueDescription" SG_ 792 Hnads_Off_Detected_States_VD_S "0x0：Invalid

0x1：Valid";
BA_ "SignalPosition" SG_ 792 Hnads_Off_Detected_States_VD_S "3.6";
BA_ "SignalValueDescription" SG_ 792 StrngWhlTorqVD_S "0x0：Invalid

0x1：Valid";
BA_ "SignalPosition" SG_ 792 StrngWhlTorqVD_S "3.7";
BA_ "SignalValueDescription" SG_ 792 StrngWhlTorq_S "PH=INT*0.01Nm

INT∈[0xB1E，0x4E2]

PH∈[-12.50，12.50]Nm

Resolution：0.01Nm

Left：Positive

Right：Negative";
BA_ "SignalPosition" SG_ 792 StrngWhlTorq_S "4.0-5.3";
BA_ "SignalValueDescription" SG_ 792 Counter318_S "PH∈[0，15]";
BA_ "SignalPosition" SG_ 792 Counter318_S "7.4-7.7";
BA_ "SignalValueDescription" SG_ 792 Checksum318_S "Checksum=（Byte1+Byte2+……+Byte7)XOR0xFF";
BA_ "SignalPosition" SG_ 792 Checksum318_S "8.0-8.7";
BA_ "GenSigInvalidValue" SG_ 790 RSF_Output_Speed_Limit_S 15;
BA_ "SignalValueDescription" SG_ 790 RSF_Output_Speed_Limit_S "0x0：NoDisplay

0x1：SPLCancelled

0x2：SPL5

0x3：SPL10

0x4：SPL15

0x5：SPL20

0x6：SPL25

……

0x1B：SPL130

0x1C-0xFF：Reserved";
BA_ "SignalPosition" SG_ 790 RSF_Output_Speed_Limit_S "6.0-6.7";
BA_ "GenSigInvalidValue" SG_ 790 RSF_function_status_S 15;
BA_ "SignalValueDescription" SG_ 790 RSF_function_status_S "0x0：Off

0x1：Fusion Mode

0x2：Vision Mode

0x3：Navigation Only Mode

0x4：Defect";
BA_ "SignalPosition" SG_ 790 RSF_function_status_S "4.5-4.7";
BA_ "GenSigInvalidValue" SG_ 790 RSF_Output_Speed_Limit_Unit_S 15;
BA_ "SignalValueDescription" SG_ 790 RSF_Output_Speed_Limit_Unit_S "0x0：Unknown

0x1：KMH

0x2：MPH

0x3：Reserved";
BA_ "SignalPosition" SG_ 790 RSF_Output_Speed_Limit_Unit_S "5.0-5.1";
BA_ "SignalPosition" SG_ 790 Over_Temperature "2.7";
BA_ "SignalValueDescription" SG_ 790 Over_Temperature "0x0：Normal

0x1：OverTemp";
BA_ "GenSigInvalidValue" SG_ 790 Left_Line_Tracking_Status_S 15;
BA_ "SignalValueDescription" SG_ 790 Left_Line_Tracking_Status_S "0x0：No Display

0x1：Line Tracking

0x2：Intervention

0x3：Warning";
BA_ "SignalPosition" SG_ 790 Left_Line_Tracking_Status_S "1.4-1.5";
BA_ "GenSigInvalidValue" SG_ 790 Lane_Assistant_Mode_Status_S 15;
BA_ "SignalValueDescription" SG_ 790 Lane_Assistant_Mode_Status_S "0x0：关闭

0x1：车道偏离

0x2：车道保持/车道纠偏

0x3：全功能";
BA_ "SignalPosition" SG_ 790 Lane_Assistant_Mode_Status_S "1.6-1.7";
BA_ "GenSigInvalidValue" SG_ 790 LKS_Sensitivity_S 15;
BA_ "SignalValueDescription" SG_ 790 LKS_Sensitivity_S "0x0：Low Sensitivity

0x1：High Sensitivity

0x2：Reserved

0x3：Reserved";
BA_ "SignalPosition" SG_ 790 LKS_Sensitivity_S "2.0-2.1";
BA_ "GenSigInvalidValue" SG_ 790 MPC_Take_Over_Req_S 15;
BA_ "SignalValueDescription" SG_ 790 MPC_Take_Over_Req_S "0x0：Inactive

0x1：Active";
BA_ "SignalPosition" SG_ 790 MPC_Take_Over_Req_S "2.2";
BA_ "GenSigInvalidValue" SG_ 790 LDP_LDW_Camera_Blocked_S 15;
BA_ "SignalValueDescription" SG_ 790 LDP_LDW_Camera_Blocked_S "0x0：正常

0x1：Camera Blocked";
BA_ "SignalPosition" SG_ 790 LDP_LDW_Camera_Blocked_S "2.3";
BA_ "GenSigInvalidValue" SG_ 790 LDP_Fault_S 15;
BA_ "SignalValueDescription" SG_ 790 LDP_Fault_S "0x0：正常

0x1：LKS Fault";
BA_ "SignalPosition" SG_ 790 LDP_Fault_S "2.4";
BA_ "GenSigInvalidValue" SG_ 790 LDW_fault1_S 15;
BA_ "SignalValueDescription" SG_ 790 LDW_fault1_S "0x0：正常

0x1：LDW Fault";
BA_ "SignalPosition" SG_ 790 LDW_fault1_S "2.5";
BA_ "GenSigInvalidValue" SG_ 790 ACC_AEB_Camera_Blocked_Infro_S 15;
BA_ "SignalValueDescription" SG_ 790 ACC_AEB_Camera_Blocked_Infro_S "0x0：No Display

0x1：ACCAEB Camera Block";
BA_ "SignalPosition" SG_ 790 ACC_AEB_Camera_Blocked_Infro_S "2.6";
BA_ "GenSigInvalidValue" SG_ 790 Output_LKS_torque_request_S 15;
BA_ "SignalValueDescription" SG_ 790 Output_LKS_torque_request_S "PH=INT*0.01Nm

INT∈[0x400，0x3FF]

PH∈[-10.24，10.23]Nm

Resolution：0.01Nm

Left：Positive

Right：Negative";
BA_ "SignalPosition" SG_ 790 Output_LKS_torque_request_S "3.0-4.2";
BA_ "GenSigInvalidValue" SG_ 790 LKS_torque_request_staus_S 15;
BA_ "SignalValueDescription" SG_ 790 LKS_torque_request_staus_S "0x0：Inhibited

0x1：Ready

0x2：Active

0x3：Reserved";
BA_ "SignalPosition" SG_ 790 LKS_torque_request_staus_S "4.3-4.4";
BA_ "GenSigInvalidValue" SG_ 790 Right_Line_Tracking_Stats_S 15;
BA_ "SignalValueDescription" SG_ 790 Right_Line_Tracking_Stats_S "0x0：No Display

0x1：Line Tracking

0x2：Intervention

0x3：Warning";
BA_ "SignalPosition" SG_ 790 Right_Line_Tracking_Stats_S "5.2-5.3";
BA_ "GenSigInvalidValue" SG_ 790 TJA_ICA_function_status_S 15;
BA_ "SignalValueDescription" SG_ 790 TJA_ICA_function_status_S "0x0：OFF

0x1：Passive

0x2：Active1

0x3：Active2

0x4：Fault

0x5：stand-by

0x6-0x7：Reserved";
BA_ "SignalPosition" SG_ 790 TJA_ICA_function_status_S "5.4-5.6";
BA_ "GenSigInvalidValue" SG_ 790 ALL_Function_Camera_Bloc_Infro_S 15;
BA_ "SignalValueDescription" SG_ 790 ALL_Function_Camera_Bloc_Infro_S "0x0：No Display

0x1：ALL Function Camera Block";
BA_ "SignalPosition" SG_ 790 ALL_Function_Camera_Bloc_Infro_S "5.7";
BA_ "GenSigInvalidValue" SG_ 790 LDW_Warning_Mode_Stats_S 15;
BA_ "SignalValueDescription" SG_ 790 LDW_Warning_Mode_Stats_S "0x0：仅振动

0x1：仅声音

0x2：振动+声音

0x3：预留";
BA_ "SignalPosition" SG_ 790 LDW_Warning_Mode_Stats_S "7.0-7.1";
BA_ "SignalValueDescription" SG_ 790 MPC_Take_Over_Req1_S "0x0：inactive

0x1：warning-level1

0x2：warning-level2

0x3：warning-level3";
BA_ "SignalPosition" SG_ 790 MPC_Take_Over_Req1_S "7.2-7.3";
BA_ "GenSigInvalidValue" SG_ 790 Message_Alive_Counter316_S 15;
BA_ "SignalValueDescription" SG_ 790 Message_Alive_Counter316_S "PH∈[0，15]";
BA_ "SignalPosition" SG_ 790 Message_Alive_Counter316_S "7.4-7.7";
BA_ "GenSigInvalidValue" SG_ 790 Messge_Checksum316_S 15;
BA_ "SignalValueDescription" SG_ 790 Messge_Checksum316_S "Checksum=(Byte1+Byte2…+Byte7)XOR0xFF";
BA_ "SignalPosition" SG_ 790 Messge_Checksum316_S "8.0-8.7";
BA_ "SignalValueDescription" SG_ 1074 ADS_System_Status_S "0x0：Normal

0x1：5R平台

0x2：13V平台

0x3：5R10V平台

0x4~0xF：Reserved";
BA_ "SignalPosition" SG_ 1074 ADS_System_Status_S "4.4-4.7";
BA_ "SignalValueDescription" SG_ 1074 CSW_Assemble_Status_S "0x0：YES

0x1：NO";
BA_ "SignalPosition" SG_ 1074 CSW_Assemble_Status_S "4.3";
BA_ "SignalValueDescription" SG_ 1074 UNP_Assemble_Status_S "0x0：YES

0x1：NO";
BA_ "SignalPosition" SG_ 1074 UNP_Assemble_Status_S "4.2";
BA_ "SignalValueDescription" SG_ 1074 FCTB_Assemble_Status_S "0x0：YES

0x1：NO";
BA_ "SignalPosition" SG_ 1074 FCTB_Assemble_Status_S "3.1";
BA_ "GenSigInvalidValue" SG_ 1074 ACC_Assemble_Status_S 15;
BA_ "SignalValueDescription" SG_ 1074 ACC_Assemble_Status_S "0x0：NO

0x1：YES";
BA_ "SignalPosition" SG_ 1074 ACC_Assemble_Status_S "1.0";
BA_ "GenSigInvalidValue" SG_ 1074 AEB_Assemble_Status_S 15;
BA_ "SignalValueDescription" SG_ 1074 AEB_Assemble_Status_S "0x0：NO

0x1：YES";
BA_ "SignalPosition" SG_ 1074 AEB_Assemble_Status_S "1.1";
BA_ "GenSigInvalidValue" SG_ 1074 FCW_Assemble_Status_S 15;
BA_ "SignalValueDescription" SG_ 1074 FCW_Assemble_Status_S "0x0：NO

0x1：YES";
BA_ "SignalPosition" SG_ 1074 FCW_Assemble_Status_S "1.2";
BA_ "GenSigInvalidValue" SG_ 1074 HMA_Assemble_Status_S 15;
BA_ "SignalValueDescription" SG_ 1074 HMA_Assemble_Status_S "0x0：NO

0x1：YES";
BA_ "SignalPosition" SG_ 1074 HMA_Assemble_Status_S "1.3";
BA_ "GenSigInvalidValue" SG_ 1074 LDW_Assemble_Status_S 15;
BA_ "SignalValueDescription" SG_ 1074 LDW_Assemble_Status_S "0x0：NO

0x1：YES";
BA_ "SignalPosition" SG_ 1074 LDW_Assemble_Status_S "1.4";
BA_ "GenSigInvalidValue" SG_ 1074 LKS_Assemble_Status_S 15;
BA_ "SignalValueDescription" SG_ 1074 LKS_Assemble_Status_S "0x0：NO

0x1：YES";
BA_ "SignalPosition" SG_ 1074 LKS_Assemble_Status_S "1.5";
BA_ "GenSigInvalidValue" SG_ 1074 TSR_Assemble_Status_S 15;
BA_ "SignalValueDescription" SG_ 1074 TSR_Assemble_Status_S "0x0：NO

0x1：YES";
BA_ "SignalPosition" SG_ 1074 TSR_Assemble_Status_S "1.6";
BA_ "GenSigInvalidValue" SG_ 1074 TJA_ICA_Assemble_Status_S 15;
BA_ "SignalValueDescription" SG_ 1074 TJA_ICA_Assemble_Status_S "0x0：NO

0x1：YES";
BA_ "SignalPosition" SG_ 1074 TJA_ICA_Assemble_Status_S "1.7";
BA_ "GenSigInvalidValue" SG_ 1074 Module_Manufacturer_S 15;
BA_ "SignalValueDescription" SG_ 1074 Module_Manufacturer_S "0x0：十五部

0x1：博世

0x2：Veoneer

0x3：Conti

0x4：ZF

0x5-0xF：预留";
BA_ "SignalPosition" SG_ 1074 Module_Manufacturer_S "2.0-2.3";
BA_ "GenSigInvalidValue" SG_ 1074 LDW_Warning_Conf_Exchange_S 15;
BA_ "SignalValueDescription" SG_ 1074 LDW_Warning_Conf_Exchange_S "0x0：NO

0x1：YES";
BA_ "SignalPosition" SG_ 1074 LDW_Warning_Conf_Exchange_S "2.4";
BA_ "SignalValueDescription" SG_ 1074 TJA_ICA_SoftKeys_S "0x0：NO

0x1：YES";
BA_ "SignalPosition" SG_ 1074 TJA_ICA_SoftKeys_S "2.5";
BA_ "SignalValueDescription" SG_ 1074 LDP_Assemble_Status_S "0x0：YES

0x1：NO";
BA_ "SignalPosition" SG_ 1074 LDP_Assemble_Status_S "2.6";
BA_ "SignalValueDescription" SG_ 1074 ELK_Assemble_Status_S "0x0：YES

0x1：NO";
BA_ "SignalPosition" SG_ 1074 ELK_Assemble_Status_S "2.7";
BA_ "SignalValueDescription" SG_ 1074 FCTA_Assemble_Status_S "0x0：YES

0x1：NO";
BA_ "SignalPosition" SG_ 1074 FCTA_Assemble_Status_S "3";
BA_ "SignalValueDescription" SG_ 1074 ISLI_Assemble_Statue_S "0x0：YES

0x1：NO";
BA_ "SignalPosition" SG_ 1074 ISLI_Assemble_Statue_S "3.2";
BA_ "SignalValueDescription" SG_ 1074 HNP_Assemble_Status_S "0x0：YES

0x1：NO";
BA_ "SignalPosition" SG_ 1074 HNP_Assemble_Status_S "3.3";
BA_ "SignalValueDescription" SG_ 1074 ILCA_Assemble_Status_S "0x0：YES

0x1：NO";
BA_ "SignalPosition" SG_ 1074 ILCA_Assemble_Status_S "3.4";
BA_ "SignalValueDescription" SG_ 1074 TLA_Assemble_Status_S "0x0：YES

0x1：NO";
BA_ "SignalPosition" SG_ 1074 TLA_Assemble_Status_S "3.5";
BA_ "SignalValueDescription" SG_ 1074 ISLC_Assemble_Status_S "0x0：YES

0x1：NO";
BA_ "SignalPosition" SG_ 1074 ISLC_Assemble_Status_S "3.6";
BA_ "SignalValueDescription" SG_ 1074 ESA_Assemble_Status_S "0x0：YES

0x1：NO";
BA_ "SignalPosition" SG_ 1074 ESA_Assemble_Status_S "3.7";
BA_ "SignalValueDescription" SG_ 1074 FCW_UI_Assemble_Status_S "0x0：New

0x1：Old";
BA_ "SignalPosition" SG_ 1074 FCW_UI_Assemble_Status_S "4";
BA_ "SignalValueDescription" SG_ 1074 Meter_Display_Mode_S "0x0：三车道

0x1：单车道";
BA_ "SignalPosition" SG_ 1074 Meter_Display_Mode_S "4.1";
BA_ "GenSigInvalidValue" SG_ 884 Target_Type_374s5_S 15;
BA_ "SignalValueDescription" SG_ 884 Target_Type_374s5_S "0x0：无效

0x1：四轮车

0x2：大型车（待定）

0x3：两轮车

0x4：行人

0x5：动物（待定）

0x6-0xF：预留";
BA_ "SignalPosition" SG_ 884 Target_Type_374s5_S "6.4-6.7";
BA_ "GenSigInvalidValue" SG_ 884 Target_State_B1_374s5_S 15;
BA_ "SignalValueDescription" SG_ 884 Target_State_B1_374s5_S "0x0：无目标

0x1：目标锁定";
BA_ "SignalPosition" SG_ 884 Target_State_B1_374s5_S "6.3";
BA_ "GenSigInvalidValue" SG_ 884 Target_State_B6_374s5_S 15;
BA_ "SignalValueDescription" SG_ 884 Target_State_B6_374s5_S "0x0：无目标

0x1：同向行驶目标锁定

0x2：对向行驶目标锁定

0x3：预留";
BA_ "SignalPosition" SG_ 884 Target_State_B6_374s5_S "6.0-6.1";
BA_ "GenSigInvalidValue" SG_ 884 Lock_Target_Ordinate_374s5_S 15;
BA_ "SignalValueDescription" SG_ 884 Lock_Target_Ordinate_374s5_S "PH=INT-100pot

INT∈[0x00，0xC8]

PH∈[-100，100]

默认值：0x00

预留值：0xC9-0xFE

无效值：0xFF";
BA_ "SignalPosition" SG_ 884 Lock_Target_Ordinate_374s5_S "3.0-3.7";
BA_ "GenSigInvalidValue" SG_ 884 Lock_Target_Abscissa_374s5_S 15;
BA_ "SignalValueDescription" SG_ 884 Lock_Target_Abscissa_374s5_S "PH=INT*1-100pot

PH∈[-100，100]

INT∈[0x0，0xF0]

默认值：0x0

预留值：0xF1-0xFE

无效值：0xFF";
BA_ "SignalPosition" SG_ 884 Lock_Target_Abscissa_374s5_S "2.0-2.7";
BA_ "GenSigInvalidValue" SG_ 884 Goal_Late_Relative_Spd_374s5_S 15;
BA_ "SignalValueDescription" SG_ 884 Goal_Late_Relative_Spd_374s5_S "PH=INT*1km/h

INT∈[0x00，0xFE]

PH∈[0，254]

默认值：0x00

无效值：0xFF";
BA_ "SignalPosition" SG_ 884 Goal_Late_Relative_Spd_374s5_S "5.0-5.7";
BA_ "SignalValueDescription" SG_ 884 Goal_Length_Relative_Spd_374s5_S "PH=INT*1km/h

INT∈[0x00，0xFE]

PH∈[0，254]

默认值：0x00

无效值：0xFF";
BA_ "SignalPosition" SG_ 884 Goal_Length_Relative_Spd_374s5_S "4.0-4.7";
BA_ "GenSigInvalidValue" SG_ 884 Goal_Length_Relative_Spd_374s5_S 15;
BA_ "GenSigInvalidValue" SG_ 884 AliveCounter_374s5_S 15;
BA_ "SignalValueDescription" SG_ 884 AliveCounter_374s5_S "[0，15]";
BA_ "SignalPosition" SG_ 884 AliveCounter_374s5_S "7.4-7.7";
BA_ "GenSigInvalidValue" SG_ 884 CheckSum_374s5_S 15;
BA_ "SignalValueDescription" SG_ 884 CheckSum_374s5_S "Checksum=(Byte1+Byte2…+Byte7)XOR0xFF";
BA_ "SignalPosition" SG_ 884 CheckSum_374s5_S "8.0-8.7";
BA_ "GenSigInvalidValue" SG_ 884 Child_ID_374_S 1;
BA_ "GenSigStartValue" SG_ 884 Child_ID_374_S 1;
BA_ "SignalValueDescription" SG_ 884 Child_ID_374_S "0x01：Left_Obj左相邻车道车前目标";
BA_ "SignalPosition" SG_ 884 Child_ID_374_S "1.0-1.7";
BA_ "GenSigInvalidValue" SG_ 884 Lock_Target_Abscissa_374s1_S 15;
BA_ "SignalValueDescription" SG_ 884 Lock_Target_Abscissa_374s1_S "PH=INT*1-100pot

PH∈[-100，100]

INT∈[0x0，0xF0]

默认值：0x0

预留值：0xF1-0xFE

无效值：0xFF";
BA_ "SignalPosition" SG_ 884 Lock_Target_Abscissa_374s1_S "2.0-2.7";
BA_ "GenSigInvalidValue" SG_ 884 Lock_Target_Ordinate_374s1_S 15;
BA_ "SignalValueDescription" SG_ 884 Lock_Target_Ordinate_374s1_S "PH=INT-100pot

INT∈[0x00，0xC8]

PH∈[-100，100]

默认值：0x00

预留值：0xC9-0xFE

无效值：0xFF";
BA_ "SignalPosition" SG_ 884 Lock_Target_Ordinate_374s1_S "3.0-3.7";
BA_ "GenSigInvalidValue" SG_ 884 Goal_Length_Relative_Spd_374s1_S 15;
BA_ "SignalValueDescription" SG_ 884 Goal_Length_Relative_Spd_374s1_S "PH=INT*1km/h

INT∈[0x00，0xFE]

PH∈[0，254]

默认值：0x00

无效值：0xFF";
BA_ "SignalPosition" SG_ 884 Goal_Length_Relative_Spd_374s1_S "4.0-4.7";
BA_ "GenSigInvalidValue" SG_ 884 Goal_Late_Relative_Spd_374s1_S 15;
BA_ "SignalValueDescription" SG_ 884 Goal_Late_Relative_Spd_374s1_S "PH=INT*1km/h

INT∈[0x00，0xFE]

PH∈[0，254]

默认值：0x00

无效值：0xFF";
BA_ "SignalPosition" SG_ 884 Goal_Late_Relative_Spd_374s1_S "5.0-5.7";
BA_ "GenSigInvalidValue" SG_ 884 Target_State_B6_374s1_S 15;
BA_ "SignalValueDescription" SG_ 884 Target_State_B6_374s1_S "0x0：无目标

0x1：同向行驶目标锁定

0x2：对向行驶目标锁定

0x3：预留";
BA_ "SignalPosition" SG_ 884 Target_State_B6_374s1_S "6.0-6.1";
BA_ "GenSigInvalidValue" SG_ 884 Target_State_B1_374s1_S 15;
BA_ "SignalValueDescription" SG_ 884 Target_State_B1_374s1_S "0x0：无目标

0x1：目标锁定";
BA_ "SignalPosition" SG_ 884 Target_State_B1_374s1_S "6.3";
BA_ "GenSigInvalidValue" SG_ 884 Target_Type_374s1_S 15;
BA_ "SignalValueDescription" SG_ 884 Target_Type_374s1_S "0x0：无效

0x1：四轮车

0x2：大型车（待定）

0x3：两轮车

0x4：行人

0x5：动物（待定）

0x6-0xF：预留";
BA_ "SignalPosition" SG_ 884 Target_Type_374s1_S "6.4-6.7";
BA_ "GenSigInvalidValue" SG_ 884 AliveCounter_374s1_S 15;
BA_ "SignalValueDescription" SG_ 884 AliveCounter_374s1_S "[0，15]";
BA_ "SignalPosition" SG_ 884 AliveCounter_374s1_S "7.4-7.7";
BA_ "GenSigInvalidValue" SG_ 884 CheckSum_374s1_S 15;
BA_ "SignalValueDescription" SG_ 884 CheckSum_374s1_S "Checksum=(Byte1+Byte2…+Byte7)XOR0xFF";
BA_ "SignalPosition" SG_ 884 CheckSum_374s1_S "8.0-8.7";
BA_ "GenSigInvalidValue" SG_ 884 Lock_Target_Abscissa_374s2_S 15;
BA_ "SignalValueDescription" SG_ 884 Lock_Target_Abscissa_374s2_S "PH=INT*1-100pot

PH∈[-100，100]

INT∈[0x0，0xF0]

默认值：0x0

预留值：0xF1-0xFE

无效值：0xFF";
BA_ "SignalPosition" SG_ 884 Lock_Target_Abscissa_374s2_S "2.0-2.7";
BA_ "GenSigInvalidValue" SG_ 884 Lock_Target_Ordinate_374s2_S 15;
BA_ "SignalValueDescription" SG_ 884 Lock_Target_Ordinate_374s2_S "PH=INT-100pot

INT∈[0x00，0xC8]

PH∈[-100，100]

默认值：0x00

预留值：0xC9-0xFE

无效值：0xFF";
BA_ "SignalPosition" SG_ 884 Lock_Target_Ordinate_374s2_S "3.0-3.7";
BA_ "GenSigInvalidValue" SG_ 884 Goal_Length_Relative_Spd_374s2_S 15;
BA_ "SignalValueDescription" SG_ 884 Goal_Length_Relative_Spd_374s2_S "PH=INT*1km/h

INT∈[0x00，0xFE]

PH∈[0，254]

默认值：0x00

无效值：0xFF";
BA_ "SignalPosition" SG_ 884 Goal_Length_Relative_Spd_374s2_S "4.0-4.7";
BA_ "GenSigInvalidValue" SG_ 884 Goal_Late_Relative_Spd_374s2_S 15;
BA_ "SignalValueDescription" SG_ 884 Goal_Late_Relative_Spd_374s2_S "PH=INT*1km/h

INT∈[0x00，0xFE]

PH∈[0，254]

默认值：0x00

无效值：0xFF";
BA_ "SignalPosition" SG_ 884 Goal_Late_Relative_Spd_374s2_S "5.0-5.7";
BA_ "GenSigInvalidValue" SG_ 884 Target_State_B6_374s2_S 15;
BA_ "SignalValueDescription" SG_ 884 Target_State_B6_374s2_S "0x0：无目标

0x1：同向行驶目标锁定

0x2：对向行驶目标锁定

0x3：预留";
BA_ "SignalPosition" SG_ 884 Target_State_B6_374s2_S "6.0-6.1";
BA_ "GenSigInvalidValue" SG_ 884 Target_State_B1_374s2_S 15;
BA_ "SignalValueDescription" SG_ 884 Target_State_B1_374s2_S "0x0：无目标

0x1：目标锁定";
BA_ "SignalPosition" SG_ 884 Target_State_B1_374s2_S "6.3";
BA_ "GenSigInvalidValue" SG_ 884 Target_Type_374s2_S 15;
BA_ "SignalValueDescription" SG_ 884 Target_Type_374s2_S "0x0：无效

0x1：四轮车

0x2：大型车（待定）

0x3：两轮车

0x4：行人

0x5：动物（待定）

0x6-0xF：预留";
BA_ "SignalPosition" SG_ 884 Target_Type_374s2_S "6.4-6.7";
BA_ "GenSigInvalidValue" SG_ 884 AliveCounter_374s2_S 15;
BA_ "SignalValueDescription" SG_ 884 AliveCounter_374s2_S "[0，15]";
BA_ "SignalPosition" SG_ 884 AliveCounter_374s2_S "7.4-7.7";
BA_ "GenSigInvalidValue" SG_ 884 CheckSum_374s2_S 15;
BA_ "SignalValueDescription" SG_ 884 CheckSum_374s2_S "Checksum=(Byte1+Byte2…+Byte7)XOR0xFF";
BA_ "SignalPosition" SG_ 884 CheckSum_374s2_S "8.0-8.7";
BA_ "GenSigInvalidValue" SG_ 884 Lock_Target_Abscissa_374s3_S 15;
BA_ "SignalValueDescription" SG_ 884 Lock_Target_Abscissa_374s3_S "PH=INT*1-100pot

PH∈[-100，100]

INT∈[0x0，0xF0]

默认值：0x0

预留值：0xF1-0xFE

无效值：0xFF";
BA_ "SignalPosition" SG_ 884 Lock_Target_Abscissa_374s3_S "2.0-2.7";
BA_ "GenSigInvalidValue" SG_ 884 Lock_Target_Ordinate_374s3_S 15;
BA_ "SignalValueDescription" SG_ 884 Lock_Target_Ordinate_374s3_S "PH=INT-100pot

INT∈[0x00，0xC8]

PH∈[-100，100]

默认值：0x00

预留值：0xC9-0xFE

无效值：0xFF";
BA_ "SignalPosition" SG_ 884 Lock_Target_Ordinate_374s3_S "3.0-3.7";
BA_ "GenSigInvalidValue" SG_ 884 Goal_Length_Relative_Spd_374s3_S 15;
BA_ "SignalValueDescription" SG_ 884 Goal_Length_Relative_Spd_374s3_S "PH=INT*1km/h

INT∈[0x00，0xFE]

PH∈[0，254]

默认值：0x00

无效值：0xFF";
BA_ "SignalPosition" SG_ 884 Goal_Length_Relative_Spd_374s3_S "4.0-4.7";
BA_ "GenSigInvalidValue" SG_ 884 Goal_Late_Relative_Spd_374s3_S 15;
BA_ "SignalValueDescription" SG_ 884 Goal_Late_Relative_Spd_374s3_S "PH=INT*1km/h

INT∈[0x00，0xFE]

PH∈[0，254]

默认值：0x00

无效值：0xFF";
BA_ "SignalPosition" SG_ 884 Goal_Late_Relative_Spd_374s3_S "5.0-5.7";
BA_ "GenSigInvalidValue" SG_ 884 Target_State_B6_374s3_S 15;
BA_ "SignalValueDescription" SG_ 884 Target_State_B6_374s3_S "0x0：无目标

0x1：同向行驶目标锁定

0x2：对向行驶目标锁定

0x3：预留";
BA_ "SignalPosition" SG_ 884 Target_State_B6_374s3_S "6.0-6.1";
BA_ "GenSigInvalidValue" SG_ 884 Target_State_B1_374s3_S 15;
BA_ "SignalValueDescription" SG_ 884 Target_State_B1_374s3_S "0x0：无目标

0x1：目标锁定";
BA_ "SignalPosition" SG_ 884 Target_State_B1_374s3_S "6.3";
BA_ "GenSigInvalidValue" SG_ 884 Target_Type_374s3_S 15;
BA_ "SignalValueDescription" SG_ 884 Target_Type_374s3_S "0x0：无效

0x1：四轮车

0x2：大型车（待定）

0x3：两轮车

0x4：行人

0x5：动物（待定）

0x6-0xF：预留";
BA_ "SignalPosition" SG_ 884 Target_Type_374s3_S "6.4-6.7";
BA_ "GenSigInvalidValue" SG_ 884 AliveCounter_374s3_S 15;
BA_ "SignalValueDescription" SG_ 884 AliveCounter_374s3_S "[0，15]";
BA_ "SignalPosition" SG_ 884 AliveCounter_374s3_S "7.4-7.7";
BA_ "GenSigInvalidValue" SG_ 884 CheckSum_374s3_S 15;
BA_ "SignalValueDescription" SG_ 884 CheckSum_374s3_S "Checksum=(Byte1+Byte2…+Byte7)XOR0xFF";
BA_ "SignalPosition" SG_ 884 CheckSum_374s3_S "8.0-8.7";
BA_ "GenSigInvalidValue" SG_ 884 Lock_Target_Abscissa_374s4_S 15;
BA_ "SignalValueDescription" SG_ 884 Lock_Target_Abscissa_374s4_S "PH=INT*1-100pot

PH∈[-100，100]

INT∈[0x0，0xF0]

默认值：0x0

预留值：0xF1-0xFE

无效值：0xFF";
BA_ "SignalPosition" SG_ 884 Lock_Target_Abscissa_374s4_S "2.0-2.7";
BA_ "GenSigInvalidValue" SG_ 884 Lock_Target_Ordinate_374s4_S 15;
BA_ "SignalValueDescription" SG_ 884 Lock_Target_Ordinate_374s4_S "PH=INT-100pot

INT∈[0x00，0xC8]

PH∈[-100，100]

默认值：0x00

预留值：0xC9-0xFE

无效值：0xFF";
BA_ "SignalPosition" SG_ 884 Lock_Target_Ordinate_374s4_S "3.0-3.7";
BA_ "GenSigInvalidValue" SG_ 884 Goal_Length_Relative_Spd_374s4_S 15;
BA_ "SignalValueDescription" SG_ 884 Goal_Length_Relative_Spd_374s4_S "PH=INT*1km/h

INT∈[0x00，0xFE]

PH∈[0，254]

默认值：0x00

无效值：0xFF";
BA_ "SignalPosition" SG_ 884 Goal_Length_Relative_Spd_374s4_S "4.0-4.7";
BA_ "GenSigInvalidValue" SG_ 884 Goal_Late_Relative_Spd_374s4_S 15;
BA_ "SignalValueDescription" SG_ 884 Goal_Late_Relative_Spd_374s4_S "PH=INT*1km/h

INT∈[0x00，0xFE]

PH∈[0，254]

默认值：0x00

无效值：0xFF";
BA_ "SignalPosition" SG_ 884 Goal_Late_Relative_Spd_374s4_S "5.0-5.7";
BA_ "GenSigInvalidValue" SG_ 884 Target_State_B6_374s4_S 15;
BA_ "SignalValueDescription" SG_ 884 Target_State_B6_374s4_S "0x0：无目标

0x1：同向行驶目标锁定

0x2：对向行驶目标锁定

0x3：预留";
BA_ "SignalPosition" SG_ 884 Target_State_B6_374s4_S "6.0-6.1";
BA_ "GenSigInvalidValue" SG_ 884 Target_State_B1_374s4_S 15;
BA_ "SignalValueDescription" SG_ 884 Target_State_B1_374s4_S "0x0：无目标

0x1：目标锁定";
BA_ "SignalPosition" SG_ 884 Target_State_B1_374s4_S "6.3";
BA_ "GenSigInvalidValue" SG_ 884 Target_Type_374s4_S 15;
BA_ "SignalValueDescription" SG_ 884 Target_Type_374s4_S "0x0：无效

0x1：四轮车

0x2：大型车（待定）

0x3：两轮车

0x4：行人

0x5：动物（待定）

0x6-0xF：预留";
BA_ "SignalPosition" SG_ 884 Target_Type_374s4_S "6.4-6.7";
BA_ "GenSigInvalidValue" SG_ 884 AliveCounter_374s4_S 15;
BA_ "SignalValueDescription" SG_ 884 AliveCounter_374s4_S "[0，15]";
BA_ "SignalPosition" SG_ 884 AliveCounter_374s4_S "7.4-7.7";
BA_ "GenSigInvalidValue" SG_ 884 CheckSum_374s4_S 15;
BA_ "SignalValueDescription" SG_ 884 CheckSum_374s4_S "Checksum=(Byte1+Byte2…+Byte7)XOR0xFF";
BA_ "SignalPosition" SG_ 884 CheckSum_374s4_S "8.0-8.7";
BA_ "GenSigInvalidValue" SG_ 843 Left_Lane_Line_Type_S 15;
BA_ "SignalValueDescription" SG_ 843 Left_Lane_Line_Type_S "0x0：未检测到车道线

0x1：实线

0x2：虚线

0x3：路沿石";
BA_ "SignalPosition" SG_ 843 Left_Lane_Line_Type_S "1.0-1.1";
BA_ "GenSigInvalidValue" SG_ 843 Right_Lane_Line_Type_S 15;
BA_ "SignalValueDescription" SG_ 843 Right_Lane_Line_Type_S "0x0：未检测到车道线

0x1：实线

0x2：虚线

0x3：路沿石";
BA_ "SignalPosition" SG_ 843 Right_Lane_Line_Type_S "1.2-1.3";
BA_ "GenSigInvalidValue" SG_ 843 Left_Lane_Line_Y_Distance_S 15;
BA_ "SignalValueDescription" SG_ 843 Left_Lane_Line_Y_Distance_S "PH=INT*0.00390625-8

PH∈[-8，7.9960938]

INT∈[0x0，0xFFFA]

默认值：0x9E0";
BA_ "SignalPosition" SG_ 843 Left_Lane_Line_Y_Distance_S "1.4-2.7";
BA_ "GenSigInvalidValue" SG_ 843 Right_Lane_Line_Y_Distance_S 15;
BA_ "SignalValueDescription" SG_ 843 Right_Lane_Line_Y_Distance_S "PH=INT*0.00390625-8

PH∈[-8，7.9960938]

INT∈[0x0，0xFFFA]

默认值：0x9E0";
BA_ "SignalPosition" SG_ 843 Right_Lane_Line_Y_Distance_S "3.0-4.3";
BA_ "GenSigInvalidValue" SG_ 843 Lane_Line_Curvature_S 15;
BA_ "SignalValueDescription" SG_ 843 Lane_Line_Curvature_S "PH=INT*0.000015-0.03071

PH∈[-0.030705，0.030705]

INT∈[0x0，0xFFE]

预留值：0xFFF";
BA_ "SignalPosition" SG_ 843 Lane_Line_Curvature_S "4.4-5.7";
BA_ "GenSigInvalidValue" SG_ 843 AliveCounter_34B_S 15;
BA_ "SignalValueDescription" SG_ 843 AliveCounter_34B_S "[0，15]";
BA_ "SignalPosition" SG_ 843 AliveCounter_34B_S "7.4-7.7";
BA_ "GenSigInvalidValue" SG_ 843 CheckSum_34B_S 15;
BA_ "SignalValueDescription" SG_ 843 CheckSum_34B_S "Checksum=(Byte1+Byte2…+Byte7)XOR0xFF";
BA_ "SignalPosition" SG_ 843 CheckSum_34B_S "8.0-8.7";
BA_ "GenSigInvalidValue" SG_ 813 MRR_Modulation_Status_S 3;
BA_ "SignalValueDescription" SG_ 813 MRR_Modulation_Status_S "0x0：No Failure

0x1：TimesyncFailure_ModFail

0x2：TimesyncCorrect_ModFail

0x3：Reserved";
BA_ "SignalPosition" SG_ 813 MRR_Modulation_Status_S "7.6-7.7";
BA_ "SignalValueDescription" SG_ 813 Front_Radar_FCTB_Warning_S "0x0：not_warning

0x1：AEB warning（AEB激活，HMI报警）

0x2：FCTB warning _left（左侧存在碰撞风险，FCTB激活，HMI报警）

0x3：FCTB warning _right（右侧存在碰撞风险，FCTB激活，HMI报警）

0x4：FCTB warning_left_right（左右侧存在碰撞风险，FCTB激活，HMI报警）";
BA_ "SignalPosition" SG_ 813 Front_Radar_FCTB_Warning_S "6.1-6.3";
BA_ "SignalValueDescription" SG_ 813 Set_Speed_S "PH=INT*5km/h

INT∈[0x000，0x33]

PH∈[0，255]km/h";
BA_ "SignalPosition" SG_ 813 Set_Speed_S "1.0-2.0";
BA_ "SignalValueDescription" SG_ 813 Obj_Valid_S "0x0：No Object

0x1：Target Object Detected";
BA_ "SignalPosition" SG_ 813 Obj_Valid_S "2.1";
BA_ "GenSigInvalidValue" SG_ 813 Tau_Gap_Set_S 3;
BA_ "GenSigStartValue" SG_ 813 Tau_Gap_Set_S 3;
BA_ "SignalValueDescription" SG_ 813 Tau_Gap_Set_S "0x0：tauGap_0

0x1：tauGap_1

0x2：tauGap_2

0x3：tauGap_3

0x4：tauGap_4

0x5：tauGap_5

0x6：tauGap_6

0x7：tauGap_7";
BA_ "SignalPosition" SG_ 813 Tau_Gap_Set_S "2.2-2.4";
BA_ "SignalValueDescription" SG_ 813 Dx_Tar_Obj_S "0x0：Distance_0

0x1：Distance_1

0x2：Distance_2

0x3：Distance_3

0x4：Distance_4

0x5：Distance_5

0x6：Distance_6

0x7：Distance_7";
BA_ "SignalPosition" SG_ 813 Dx_Tar_Obj_S "2.5-2.7";
BA_ "SignalValueDescription" SG_ 813 PCW_Pre_Warning_S "0x0：No Warning

0x1：Warning";
BA_ "SignalPosition" SG_ 813 PCW_Pre_Warning_S "3.0";
BA_ "SignalValueDescription" SG_ 813 PCW_Latent_Warning_S "0x0：No Warning

0x1：Warning";
BA_ "SignalPosition" SG_ 813 PCW_Latent_Warning_S "3.1";
BA_ "SignalValueDescription" SG_ 813 PCW_State_S "0x0：OFF

0x1：ON";
BA_ "SignalPosition" SG_ 813 PCW_State_S "3.2";
BA_ "SignalValueDescription" SG_ 813 ACC_Mode_Display_S "0x0：OFF Mode

0x1：PassiveMode

0x2：StandBy Mode

0x3：Active Control Mode

0x4：Brake Only Mode

0x5：Override

0x6：Reserved

0x7：Failure Mode";
BA_ "SignalPosition" SG_ 813 ACC_Mode_Display_S "3.3-3.5";
BA_ "SignalValueDescription" SG_ 813 ACC_State_S "0x0：OFF

0x1：ON";
BA_ "SignalPosition" SG_ 813 ACC_State_S "3.6";
BA_ "SignalValueDescription" SG_ 813 Take_Over_Req_S "0x0：No TakeOver Request

0x1：Valid TakeOver Request";
BA_ "SignalPosition" SG_ 813 Take_Over_Req_S "3.7";
BA_ "SignalValueDescription" SG_ 813 Speed_Unit_Set_S "0x0：无效

0x1：Km/h

0x2：MPH

0x3：预留";
BA_ "SignalPosition" SG_ 813 Speed_Unit_Set_S "4.0-4.1";
BA_ "SignalValueDescription" SG_ 813 CCR_AEB_Error_S "0x0：无显示Nodisplay

0x1：请检查AEB系统";
BA_ "SignalPosition" SG_ 813 CCR_AEB_Error_S "4.2";
BA_ "SignalValueDescription" SG_ 813 ACC_Text_Info_For_Driver_S "0x00：无显示

0x01：ACC无法激活

0x02：ACC取消

0x03：ACC已激活

0x04：超越加速中

0x05：危险请制动

0x06：预留

0x07：ACC已开启

0x08：ACC已关闭

0x09：请检查自适应巡航系统

0x0A：请确认安全带是否系上

0x0B：请确认车门是否关好

0x0C：请确认档位是否在D档";
BA_ "SignalPosition" SG_ 813 ACC_Text_Info_For_Driver_S "4.3-4.7";
BA_ "SignalValueDescription" SG_ 813 CCR_FCW_Error_S "0x0：无显示Nodisplay

0x1：请检查FCW系统";
BA_ "SignalPosition" SG_ 813 CCR_FCW_Error_S "5.0";
BA_ "SignalValueDescription" SG_ 813 Pedestrian_FCW_Brak_Error_S "0x0：无显示Nodisplay

0x1：请检查VRU系统

默认值：0x0";
BA_ "SignalPosition" SG_ 813 Pedestrian_FCW_Brak_Error_S "5.1";
BA_ "SignalValueDescription" SG_ 813 Acute_Warning_S "0x0：No Warning

0x1：Warning

默认值：0x0";
BA_ "SignalPosition" SG_ 813 Acute_Warning_S "5.3";
BA_ "SignalValueDescription" SG_ 813 AEB_State_S "0x0：OFF

0x1：ON";
BA_ "SignalPosition" SG_ 813 AEB_State_S "5.4";
BA_ "GenSigInvalidValue" SG_ 813 PCW_Level_Feedback_S 2;
BA_ "GenSigStartValue" SG_ 813 PCW_Level_Feedback_S 2;
BA_ "SignalValueDescription" SG_ 813 PCW_Level_Feedback_S "0x0：OFF

0x1：Level 1 低

0x2：Level 2 中(默认选择)

0x3：Level 3 高";
BA_ "SignalPosition" SG_ 813 PCW_Level_Feedback_S "5.5-5.6";
BA_ "SignalValueDescription" SG_ 813 ACC_Mode_Display1_S "0x0：OFF Mode

0x1：PassiveMode

0x2：StandBy Mode

0x3：Active Control Mode

0x4：Brake Only Mode

0x5：Override

0x6: stand-still active mode

0x7: stand-still wait mode

0x8: Failure mode

0x9：永久故障

0xA-0xF：Reserved";
BA_ "SignalPosition" SG_ 813 ACC_Mode_Display1_S "6.4-6.7";
BA_ "SignalValueDescription" SG_ 813 Alive_Counter32D_S "[0，15]";
BA_ "SignalPosition" SG_ 813 Alive_Counter32D_S "7.0-7.3";
BA_ "SignalValueDescription" SG_ 813 Checksum32D_S "Checksum=(Byte1+Byte2…+Byte7)XOR0xFF";
BA_ "SignalPosition" SG_ 813 Checksum32D_S "8.0-8.7";
BA_ "SignalValueDescription" SG_ 814 ACC_Axv_Cv_Aim_S "PH=INT*0.05-5[m/s2]

[0x00，0xFF]

[-5，7.75][m/s2]

默认值：0x00";
BA_ "SignalPosition" SG_ 814 ACC_Axv_Cv_Aim_S "1.0-1.7";
BA_ "SignalValueDescription" SG_ 814 Axv_Cv_Coft_Band_Upper_Val_S "PH=INT*0.05-5[m/s2]

[0x00，0xFF]

[-5，7.75][m/s2]

默认值：0x00";
BA_ "SignalPosition" SG_ 814 Axv_Cv_Coft_Band_Upper_Val_S "2.0-2.7";
BA_ "SignalValueDescription" SG_ 814 Axv_Cv_Coft_Band_Lower_Val_S "PH=INT*0.05-5[m/s2]

[0x00，0xFF]

[-5，7.75][m/s2]

默认值：0x00";
BA_ "SignalPosition" SG_ 814 Axv_Cv_Coft_Band_Lower_Val_S "3.0-3.7";
BA_ "SignalValueDescription" SG_ 814 ADt_Upper_Limit_Axv_Cv_S "PH=INT*0.2[m/s3]

[0x00，0x50]

[0，16][m/s3]

默认值：0x00";
BA_ "SignalPosition" SG_ 814 ADt_Upper_Limit_Axv_Cv_S "4.0-4.6";
BA_ "SignalValueDescription" SG_ 814 ADt_Low_Limit_Axv_Cv_S "PH=INT*0.2-16[m/s3]

[0x00，0x50]

[-16，0][m/s3]

默认值：0x00";
BA_ "SignalPosition" SG_ 814 ADt_Low_Limit_Axv_Cv_S "5.0-5.6";
BA_ "SignalValueDescription" SG_ 814 ACC_Drive_Off_Req_S "0x0：norequest

0x1：request";
BA_ "SignalPosition" SG_ 814 ACC_Drive_Off_Req_S "5.7";
BA_ "SignalValueDescription" SG_ 814 ACC_DecTo_Stop_Req_S "0x0：norequest

0x1：request";
BA_ "SignalPosition" SG_ 814 ACC_DecTo_Stop_Req_S "6.0";
BA_ "SignalValueDescription" SG_ 814 ACC_Minimum_Braking_S "0x0：nodemand

0x1：demand";
BA_ "SignalPosition" SG_ 814 ACC_Minimum_Braking_S "6.1";
BA_ "SignalValueDescription" SG_ 814 Brake_Preferred_S "0x0：nodemand

0x1：demand";
BA_ "SignalPosition" SG_ 814 Brake_Preferred_S "6.2";
BA_ "SignalValueDescription" SG_ 814 ACC_Mode_S "0x0：OFF

0x1：Passivemode

0x2：StandBymode

0x3：ActiveControlmode

0x4：BrakeOnlymode

0x5：Override

0x6：Standstill

0x7：Failuremode";
BA_ "SignalPosition" SG_ 814 ACC_Mode_S "6.3-6.5";
BA_ "SignalValueDescription" SG_ 814 ESP_VLC_Shut_Down_Request_S "0x0：Softoff

0x1：Fastoff

0x2：Immediateoff

0x3：Initial";
BA_ "SignalPosition" SG_ 814 ESP_VLC_Shut_Down_Request_S "6.6-6.7";
BA_ "SignalValueDescription" SG_ 814 Alive_Counter32E_S "[0，15]";
BA_ "SignalPosition" SG_ 814 Alive_Counter32E_S "7.0-7.3";
BA_ "SignalValueDescription" SG_ 814 Checksum32E_S "Checksum=(Byte1+Byte2…+Byte7)XOR0xFF";
BA_ "SignalPosition" SG_ 814 Checksum32E_S "8.0-8.7";
BA_ "GenSigInvalidValue" SG_ 815 MRR_MRC_Request_S 3;
BA_ "SignalValueDescription" SG_ 815 MRR_MRC_Request_S "0x0：No request

0x1：Request

0x2-0x3: Reserved";
BA_ "SignalPosition" SG_ 815 MRR_MRC_Request_S "6.4-6.5";
BA_ "GenSigInvalidValue" SG_ 815 MRR_SOS_Request_S 3;
BA_ "SignalValueDescription" SG_ 815 MRR_SOS_Request_S "0x0：No request

0x1：Request

0x2-0x3: Reserved";
BA_ "SignalPosition" SG_ 815 MRR_SOS_Request_S "6.2-6.3";
BA_ "GenSigInvalidValue" SG_ 815 SeatbeltControl_Request_S 7;
BA_ "SignalValueDescription" SG_ 815 SeatbeltControl_Request_S "0x0：No Request

0x1：Request to Shock

0x2：Request to tension

0x3:  Reserved";
BA_ "SignalPosition" SG_ 815 SeatbeltControl_Request_S "6.0-6.1";
BA_ "SignalValueDescription" SG_ 815 ELK_OT_status_S "0x0：OFF

0x1：Passive

0x2：Ative

0x3：Failure";
BA_ "SignalPosition" SG_ 815 ELK_OT_status_S "4.0-4.1";
BA_ "GenSigInvalidValue" SG_ 815 ABA_Level_S 15;
BA_ "SignalValueDescription" SG_ 815 ABA_Level_S "0x0：level0

0x1：level1

0x2：level2

0x3：level3";
BA_ "SignalPosition" SG_ 815 ABA_Level_S "3.5-3.6";
BA_ "GenSigInvalidValue" SG_ 815 ABA_Available_S 15;
BA_ "SignalValueDescription" SG_ 815 ABA_Available_S "0x0：nodemand

0x1：demand";
BA_ "SignalPosition" SG_ 815 ABA_Available_S "3.4";
BA_ "GenSigInvalidValue" SG_ 815 AEB_Ax_Tar_S 15;
BA_ "SignalValueDescription" SG_ 815 AEB_Ax_Tar_S "PH=INT*0.0004882-16[m/s2]

[0x0000，0xFFFF]

[-16，16]";
BA_ "SignalPosition" SG_ 815 AEB_Ax_Tar_S "1.0-2.7";
BA_ "GenSigInvalidValue" SG_ 815 Req_EBA_Decel_Ctrl_S 15;
BA_ "SignalValueDescription" SG_ 815 Req_EBA_Decel_Ctrl_S "0x0：nodemand

0x1：demand";
BA_ "SignalPosition" SG_ 815 Req_EBA_Decel_Ctrl_S "3.0";
BA_ "GenSigInvalidValue" SG_ 815 ESP_Prefill_Req_S 15;
BA_ "SignalValueDescription" SG_ 815 ESP_Prefill_Req_S "0x0：nodemand

0x1：demand";
BA_ "SignalPosition" SG_ 815 ESP_Prefill_Req_S "3.2";
BA_ "GenSigInvalidValue" SG_ 815 AWB_Request_S 15;
BA_ "SignalValueDescription" SG_ 815 AWB_Request_S "0x0：nodemand

0x1：demand";
BA_ "SignalPosition" SG_ 815 AWB_Request_S "3.3";
BA_ "GenSigInvalidValue" SG_ 815 AEB_DecCtrl_Request_S 15;
BA_ "SignalValueDescription" SG_ 815 AEB_DecCtrl_Request_S "0x0：nodemand

0x1：demand";
BA_ "SignalPosition" SG_ 815 AEB_DecCtrl_Request_S "3.7";
BA_ "GenSigInvalidValue" SG_ 815 AWB_Level_S 15;
BA_ "SignalValueDescription" SG_ 815 AWB_Level_S "0x0：nolevel

0x1：level1

0x2：level2

0x3：level3

0x4：level4

0x5-0xF：Reserved";
BA_ "SignalPosition" SG_ 815 AWB_Level_S "4.4-4.7";
BA_ "GenSigInvalidValue" SG_ 815 Req_ESC_Ctrl_Veh_S 1;
BA_ "GenSigStartValue" SG_ 815 Req_ESC_Ctrl_Veh_S 1;
BA_ "SignalValueDescription" SG_ 815 Req_ESC_Ctrl_Veh_S "0x0：Hold

0x1：Nothold";
BA_ "SignalPosition" SG_ 815 Req_ESC_Ctrl_Veh_S "5.0";
BA_ "SignalValueDescription" SG_ 815 ISLC_Sts_S "0x0：OFF

0x1：ON";
BA_ "SignalPosition" SG_ 815 ISLC_Sts_S "5.1";
BA_ "SignalValueDescription" SG_ 815 ELK_status_S "0x0：OFF

0x1：Passive

0x2：Active

0x3：Failure";
BA_ "SignalPosition" SG_ 815 ELK_status_S "5.2-5.3";
BA_ "SignalValueDescription" SG_ 815 ISLC_Warnning_S "0x0：NoRequest

0x1：Request按set-操作";
BA_ "SignalPosition" SG_ 815 ISLC_Warnning_S "5.4";
BA_ "SignalValueDescription" SG_ 815 ELK_Take_Over_Req_S "0x0：inactive

0x1：warning-level1

0x2：warning-level2

0x3：warning-level3";
BA_ "SignalPosition" SG_ 815 ELK_Take_Over_Req_S "5.5-5.6";
BA_ "GenSigInvalidValue" SG_ 815 Alive_Counter32F_S 15;
BA_ "SignalValueDescription" SG_ 815 Alive_Counter32F_S "[0，15]";
BA_ "SignalPosition" SG_ 815 Alive_Counter32F_S "7.0-7.3";
BA_ "GenSigInvalidValue" SG_ 815 Checksum32F_S 15;
BA_ "SignalValueDescription" SG_ 815 Checksum32F_S "Checksum=(Byte1+Byte2…+Byte7)XOR0xFF";
BA_ "SignalPosition" SG_ 815 Checksum32F_S "8.0-8.7";
VAL_ 289 Vehicle_Speed_Stats_S 1 "Invalid" 0 "Valid" ;
VAL_ 289 AWB_Available_S 1 "Available" 0 "Not Available" ;
VAL_ 289 AWB_Active_Brake_Warning_S 1 "Active" 0 "No Active" ;
VAL_ 289 AEB_Dec_Active_S 1 "Active" 0 "No Active" ;
VAL_ 289 AEB_not_Available_S 1 "Available" 0 "Not Available" ;
VAL_ 289 Prefill_Available_S 1 "Available" 0 "Not Available" ;
VAL_ 289 Prefill_Active_S 1 "Active" 0 "No Active" ;
VAL_ 289 ABAavailable_S 1 "Available" 0 "Not Available" ;
VAL_ 289 ABA_Active_S 1 "Active" 0 "No Active" ;
VAL_ 291 HHC_Fault_S 1 "Failure" 0 "No Failure" ;
VAL_ 291 ATS_Ctrl_Status_S 1 "ATSinValid" 0 "ATSValid" ;
VAL_ 291 Brake_Fluid_Warning_S 3 "Reserved" 2 "BrakeFluid_Electric_error" 1 "BrakeFluid_Empty" 0 "BrakeFluid_Normal" ;
VAL_ 291 IPB_Sport_Model_S 1 "Active  " 0 "Inactive  " ;
VAL_ 291 IPB_Func_Mode_S 1 "标准" 0 "舒适" ;
VAL_ 291 HDC_Failure_S 1 "Failure" 0 "No Failure" ;
VAL_ 291 HDC_CtrlStatus_S 3 "IPBwithoutHDC" 2 "HDCOnwithactivebraking(lampflashing)" 1 "HDCOnwithoutactivebraking(lampon)" 0 "HDCOff(nolamp)" ;
VAL_ 291 Brake_Pedal_Status_S 3 "Error" 2 "Reserved" 1 "Pressed" 0 "Not Pressed" ;
VAL_ 291 Basc_Front_S 1 "Active" 0 "Inactive" ;
VAL_ 291 Clutch_Pedal_Status_S 1 "Pressed" 0 "Not Pressed" ;
VAL_ 291 ACMH_Fault_S 1 "Failure" 0 "No Failure" ;
VAL_ 291 ESP_OFF_S 1 "ESP OFF" 0 "ESP ON" ;
VAL_ 291 ESP_Active_S 1 "Active" 0 "No Active" ;
VAL_ 291 TCS_Fault_S 1 "Failure" 0 "No Failure" ;
VAL_ 291 VDC_Fault_S 1 "Failure" 0 "No Failure" ;
VAL_ 546 EBD_Active_222_S 1 "Active" 0 "No Active" ;
VAL_ 546 ABS_Active_222_S 1 "Active" 0 "No Active" ;
VAL_ 546 EBD_Fault_222_S 1 "Failure" 0 "No Failure" ;
VAL_ 546 ABS_Fault_222_S 1 "Failure" 0 "No Failure" ;
VAL_ 546 TCS_Active_222_S 1 "Active" 0 "Not Active" ;
VAL_ 546 DWT_B_Active_222_S 1 "Active" 0 "Not Active" ;
VAL_ 546 VDC_Active_222_S 1 "Active" 0 "Not Active" ;
VAL_ 546 Yaw_Rate_Status_S 1 "Valid" 0 "Not Valid" ;
VAL_ 547 IPB_AY_Status_S 1 "Valid" 0 "Not Valid" ;
VAL_ 547 IPB_AX_Status_S 1 "Valid" 0 "Not Valid" ;
VAL_ 544 RR_Wheel_Drive_Direction_S 3 "Stop" 2 "Backward" 1 "Forward" 0 "Undefinable" ;
VAL_ 544 RL_Wheel_Drive_Direction_S 3 "Stop" 2 "Backward" 1 "Forward" 0 "Undefinable" ;
VAL_ 544 FR_Wheel_Drive_Direction_S 3 "Stop" 2 "Backward" 1 "Forward" 0 "Undefinable" ;
VAL_ 544 FL_Wheel_Drive_Direction_S 3 "Stop" 2 "Backward" 1 "Forward" 0 "Undefinable" ;
VAL_ 544 Active_Vehicle_Hold_S 1 "Active Vehicle Hold" 0 "Not Active Vehicle Hold" ;
VAL_ 544 VLC_Available_S 1 "Available" 0 "Not Available" ;
VAL_ 544 VLC_Active_S 1 "Active" 0 "No Active" ;
VAL_ 544 VLC_Fail_S 1 "Failure" 0 "No Failure" ;
VAL_ 544 No_Brake_Force_S 1 "No Brake Force" 0 "Exist Brake Force" ;
VAL_ 544 IPB_Request_EPB_S 3 "IPBRequestApb_LockBrake" 2 "IPBRequestApb_ReleaseBrake" 1 "IPBRequestApb_NoRequest" 0 "IPBRequest Apb_NotInitialized" ;
VAL_ 544 QDC_ACC_S 1 "Error" 0 "No Error" ;
VAL_ 544 ECD_Temp_Off_S 1 "Temp Too High" 0 "Not High" ;
VAL_ 544 Vlc_Prevent_Fuel_Cut_Off_S 1 "Request To Prevent Fule Cutoff" 0 "No Request To Prevent Fule Cutoff" ;
VAL_ 544 Vehicle_Stand_Still_S 3 "Reserved" 2 "Invalid(shortunavailability，max3s)" 1 "Standstill" 0 "Not Standstill" ;
VAL_ 544 FL_Wheel_Drive_Direct_Stat_S 1 "Invalid" 0 "Valid" ;
VAL_ 544 FR_Wheel_Drive_Direct_Stat_S 1 "Invalid" 0 "Valid" ;
VAL_ 544 RL_Wheel_Drive_Direct_Stat_S 1 "Invalid" 0 "Valid" ;
VAL_ 544 RR_Wheel_Drive_Direct_Stat_S 1 "Invalid" 0 "Valid" ;
VAL_ 544 VLC_Torque_Request_Status_S 1 "Active" 0 "No Active" ;
VAL_ 544 CDD_Available_S 1 "Available" 0 "No Available" ;
VAL_ 544 CDD_Active_S 1 "Active" 0 "No Active" ;
VAL_ 544 CDD_Fail_S 1 "Failure" 0 "No Failure" ;
VAL_ 1058 RR_Wheel_Puls_Count_Valid_422_S 1 "Invalid" 0 "Valid" ;
VAL_ 1058 RL_Wheel_Puls_Count_Valid_422_S 1 "Invalid" 0 "Valid" ;
VAL_ 1058 FR_Wheel_Puls_Count_Valid_422_S 1 "Invalid" 0 "Valid" ;
VAL_ 1058 FL_Wheel_Puls_Count_Valid_422_S 1 "Invalid" 0 "Valid" ;
VAL_ 496 Wheel_Speed_FR_Stats_1F0_S 1 "Invalid" 0 "Valid" ;
VAL_ 496 Wheel_Speed_FL_Stats_1F0_S 1 "Invalid" 0 "Valid" ;
VAL_ 496 Wheel_Speed_RR_Stats_1F0_S 1 "Invalid" 0 "Valid" ;
VAL_ 496 WheelSpeed_RL_Status_1F0_S 1 "Invalid" 0 "Valid" ;
VAL_ 213 IPB_Imput_Rod_Stroke_State_S 1 "Invalid" 0 "Valid" ;
VAL_ 588 Steering_Mode_Status_S 5 "车道保持模式" 4 "运动+" 3 "运动" 2 "舒适+" 1 "舒适" 0 "无效" ;
VAL_ 287 Failure_Stats_OK_S 1 "Sensor Information Valid" 0 "Sensor Information Invalid" ;
VAL_ 287 Sensor_Calibration_Stats_S 1 "Sensor1 Calibrated" 0 "Sensor Not Calibrated" ;
VAL_ 287 TRIM_Trimming_Stats_S 1 "Sensor Trimmed" 0 "Sensor Not Trimmed" ;
VAL_ 792 EPS_LKA_Control_State_S 4 "ExternalRequireorEPSPermanentlyFailed" 3 "ExternalRequireorEPSTemporaryFailed" 2 "EPSExternalSteeringTorqueRequireControlActive" 1 "EPSExternalSteeringTorqueRequireControlReady" 0 "EPSExternalSteeringTorqueRequireControlNotReady" ;
VAL_ 792 LKACtrlDlvdValue_VD_S 1 "Valid" 0 "Invalid" ;
VAL_ 792 Hnads_Off_Detected_States_S 1 "Hands Of Detected" 0 "Hands Off Not Detected" ;
VAL_ 792 Hnads_Off_Detected_States_VD_S 1 "Valid" 0 "Invalid" ;
VAL_ 792 StrngWhlTorqVD_S 1 "Valid" 0 "Invalid" ;
VAL_ 790 RSF_Output_Speed_Limit_S 27 "SPL130" 6 "SPL25" 5 "SPL20" 4 "SPL15" 3 "SPL10" 2 "SPL5" 1 "SPLCancelled" 0 "NoDisplay" ;
VAL_ 790 RSF_function_status_S 4 "Defect" 3 "Navigation Only Mode" 2 "Vision Mode" 1 "Fusion Mode" 0 "Off" ;
VAL_ 790 RSF_Output_Speed_Limit_Unit_S 3 "Reserved" 2 "MPH" 1 "KMH" 0 "Unknown" ;
VAL_ 790 Left_Line_Tracking_Status_S 3 "Warning" 2 "Intervention" 1 "Line Tracking" 0 "No Display" ;
VAL_ 790 Lane_Assistant_Mode_Status_S 3 "全功能" 2 "车道保持/车道纠偏" 1 "车道偏离" 0 "关闭" ;
VAL_ 790 LKS_Sensitivity_S 3 "Reserved" 2 "Reserved" 1 "High Sensitivity" 0 "Low Sensitivity" ;
VAL_ 790 MPC_Take_Over_Req_S 1 "Active" 0 "Inactive" ;
VAL_ 790 LDP_LDW_Camera_Blocked_S 1 "Camera Blocked" 0 "正常" ;
VAL_ 790 LDP_Fault_S 1 "LKS Fault" 0 "正常" ;
VAL_ 790 LDW_fault1_S 1 "LDW Fault" 0 "正常" ;
VAL_ 790 ACC_AEB_Camera_Blocked_Infro_S 1 "ACCAEB Camera Block" 0 "No Display" ;
VAL_ 790 LKS_torque_request_staus_S 3 "Reserved" 2 "Active" 1 "Ready" 0 "Inhibited" ;
VAL_ 790 Right_Line_Tracking_Stats_S 3 "Warning" 2 "Intervention" 1 "Line Tracking" 0 "No Display" ;
VAL_ 790 TJA_ICA_function_status_S 5 "stand-by" 4 "Fault" 3 "Active2" 2 "Active1" 1 "Passive" 0 "OFF" ;
VAL_ 790 ALL_Function_Camera_Bloc_Infro_S 1 "ALL Function Camera Block" 0 "No Display" ;
VAL_ 790 LDW_Warning_Mode_Stats_S 3 "预留" 2 "振动+声音" 1 "仅声音" 0 "仅振动" ;
VAL_ 790 MPC_Take_Over_Req1_S 3 "warning-level3" 2 "warning-level2" 1 "warning-level1" 0 "inactive" ;
VAL_ 1074 ADS_System_Status_S 3 "5R10V平台" 2 "13V平台" 1 "5R平台" 0 "Normal" ;
VAL_ 1074 CSW_Assemble_Status_S 1 "NO" 0 "YES" ;
VAL_ 1074 UNP_Assemble_Status_S 1 "NO" 0 "YES" ;
VAL_ 1074 FCTB_Assemble_Status_S 1 "NO" 0 "YES" ;
VAL_ 1074 ACC_Assemble_Status_S 1 "YES" 0 "NO" ;
VAL_ 1074 AEB_Assemble_Status_S 1 "YES" 0 "NO" ;
VAL_ 1074 FCW_Assemble_Status_S 1 "YES" 0 "NO" ;
VAL_ 1074 HMA_Assemble_Status_S 1 "YES" 0 "NO" ;
VAL_ 1074 LDW_Assemble_Status_S 1 "YES" 0 "NO" ;
VAL_ 1074 LKS_Assemble_Status_S 1 "YES" 0 "NO" ;
VAL_ 1074 TSR_Assemble_Status_S 1 "YES" 0 "NO" ;
VAL_ 1074 TJA_ICA_Assemble_Status_S 1 "YES" 0 "NO" ;
VAL_ 1074 Module_Manufacturer_S 4 "ZF" 3 "Conti" 2 "Veoneer" 1 "博世" 0 "十五部" ;
VAL_ 1074 LDW_Warning_Conf_Exchange_S 1 "YES" 0 "NO" ;
VAL_ 1074 TJA_ICA_SoftKeys_S 1 "YES" 0 "NO" ;
VAL_ 1074 LDP_Assemble_Status_S 1 "NO" 0 "YES" ;
VAL_ 1074 ELK_Assemble_Status_S 1 "NO" 0 "YES" ;
VAL_ 1074 FCTA_Assemble_Status_S 1 "NO" 0 "YES" ;
VAL_ 1074 ISLI_Assemble_Statue_S 1 "NO" 0 "YES" ;
VAL_ 1074 HNP_Assemble_Status_S 1 "NO" 0 "YES" ;
VAL_ 1074 ILCA_Assemble_Status_S 1 "NO" 0 "YES" ;
VAL_ 1074 TLA_Assemble_Status_S 1 "NO" 0 "YES" ;
VAL_ 1074 ISLC_Assemble_Status_S 1 "NO" 0 "YES" ;
VAL_ 1074 ESA_Assemble_Status_S 1 "NO" 0 "YES" ;
VAL_ 1074 FCW_UI_Assemble_Status_S 1 "Old" 0 "New" ;
VAL_ 1074 Meter_Display_Mode_S 1 "单车道" 0 "三车道" ;
VAL_ 884 Target_Type_374s5_S 5 "动物（待定）" 4 "行人" 3 "两轮车" 2 "大型车（待定）" 1 "四轮车" 0 "无效" ;
VAL_ 884 Target_State_B1_374s5_S 1 "目标锁定" 0 "无目标" ;
VAL_ 884 Target_State_B6_374s5_S 3 "预留" 2 "对向行驶目标锁定" 1 "同向行驶目标锁定" 0 "无目标" ;
VAL_ 884 Child_ID_374_S 1 "Left_Obj左相邻车道车前目标" ;
VAL_ 884 Target_State_B6_374s1_S 3 "预留" 2 "对向行驶目标锁定" 1 "同向行驶目标锁定" 0 "无目标" ;
VAL_ 884 Target_State_B1_374s1_S 1 "目标锁定" 0 "无目标" ;
VAL_ 884 Target_Type_374s1_S 5 "动物（待定）" 4 "行人" 3 "两轮车" 2 "大型车（待定）" 1 "四轮车" 0 "无效" ;
VAL_ 884 Target_State_B6_374s2_S 3 "预留" 2 "对向行驶目标锁定" 1 "同向行驶目标锁定" 0 "无目标" ;
VAL_ 884 Target_State_B1_374s2_S 1 "目标锁定" 0 "无目标" ;
VAL_ 884 Target_Type_374s2_S 5 "动物（待定）" 4 "行人" 3 "两轮车" 2 "大型车（待定）" 1 "四轮车" 0 "无效" ;
VAL_ 884 Target_State_B6_374s3_S 3 "预留" 2 "对向行驶目标锁定" 1 "同向行驶目标锁定" 0 "无目标" ;
VAL_ 884 Target_State_B1_374s3_S 1 "目标锁定" 0 "无目标" ;
VAL_ 884 Target_Type_374s3_S 5 "动物（待定）" 4 "行人" 3 "两轮车" 2 "大型车（待定）" 1 "四轮车" 0 "无效" ;
VAL_ 884 Target_State_B6_374s4_S 3 "预留" 2 "对向行驶目标锁定" 1 "同向行驶目标锁定" 0 "无目标" ;
VAL_ 884 Target_State_B1_374s4_S 1 "目标锁定" 0 "无目标" ;
VAL_ 884 Target_Type_374s4_S 5 "动物（待定）" 4 "行人" 3 "两轮车" 2 "大型车（待定）" 1 "四轮车" 0 "无效" ;
VAL_ 843 Left_Lane_Line_Type_S 3 "路沿石" 2 "虚线" 1 "实线" 0 "未检测到车道线" ;
VAL_ 843 Right_Lane_Line_Type_S 3 "路沿石" 2 "虚线" 1 "实线" 0 "未检测到车道线" ;
VAL_ 813 MRR_Modulation_Status_S 3 "Reserved" 2 "TimesyncCorrect_ModFail" 1 "TimesyncFailure_ModFail" 0 "No Failure" ;
VAL_ 813 Front_Radar_FCTB_Warning_S 4 "FCTB warning_left_right（左右侧存在碰撞风险，FCTB激活，HMI报警））" 3 "FCTB warning _right（右侧存在碰撞风险，FCTB激活，HMI报警）" 2 "FCTB warning _left（左侧存在碰撞风险，FCTB激活，HMI报警）" 1 "AEB warning（AEB激活，HMI报警）" 0 "not_warning" ;
VAL_ 813 Obj_Valid_S 1 "Target Object Detected" 0 "No Object" ;
VAL_ 813 Tau_Gap_Set_S 7 "tauGap_7" 6 "tauGap_6" 5 "tauGap_5" 4 "tauGap_4" 3 "tauGap_3" 2 "tauGap_2" 1 "tauGap_1" 0 "tauGap_0" ;
VAL_ 813 Dx_Tar_Obj_S 7 "Distance_7" 6 "Distance_6" 5 "Distance_5" 4 "Distance_4" 3 "Distance_3" 2 "Distance_2" 1 "Distance_1" 0 "Distance_0" ;
VAL_ 813 PCW_Pre_Warning_S 1 "Warning" 0 "No Warning" ;
VAL_ 813 PCW_Latent_Warning_S 1 "Warning" 0 "No Warning" ;
VAL_ 813 PCW_State_S 1 "ON" 0 "OFF" ;
VAL_ 813 ACC_Mode_Display_S 7 "Failure Mode" 6 "Reserved" 5 "Override" 4 "Brake Only Mode" 3 "Active Control Mode" 2 "StandBy Mode" 1 "PassiveMode" 0 "OFF Mode" ;
VAL_ 813 ACC_State_S 1 "ON" 0 "OFF" ;
VAL_ 813 Take_Over_Req_S 1 "Valid TakeOver Request" 0 "No TakeOver Request" ;
VAL_ 813 Speed_Unit_Set_S 3 "预留" 2 "MPH" 1 "Km/h" 0 "无效" ;
VAL_ 813 CCR_AEB_Error_S 1 "请检查AEB系统" 0 "无显示Nodisplay" ;
VAL_ 813 ACC_Text_Info_For_Driver_S 15 "前车已驶离，请踩加速踏板起步" 14 "请确认ESP功能是否开启" 13 "请确认EPB是否释放" 12 "请确认档位是否在D档" 11 "请确认车门是否关好" 10 "请确认安全带是否系上" 9 "请检查自适应巡航系统" 8 "ACC已关闭" 7 "ACC已开启" 6 "预留" 5 "危险请制动" 4 "超越加速中" 3 "ACC已激活" 2 "ACC取消" 1 "ACC无法激活" 0 "无显示" ;
VAL_ 813 CCR_FCW_Error_S 1 "请检查FCW系统" 0 "无显示Nodisplay" ;
VAL_ 813 Pedestrian_FCW_Brak_Error_S 1 "请检查VRU系统" 0 "无显示Nodisplay" ;
VAL_ 813 Acute_Warning_S 1 "Warning" 0 "No Warning" ;
VAL_ 813 AEB_State_S 1 "ON" 0 "OFF" ;
VAL_ 813 PCW_Level_Feedback_S 3 "Level 3 高" 2 "Level 2 中(默认选择)" 1 "Level 1 低" 0 "OFF" ;
VAL_ 813 ACC_Mode_Display1_S 9 "永久故障" 8 " Failure mode" 7 " stand-still wait mode" 6 " stand-still active mode" 5 "Override" 4 "Brake Only Mode" 3 "Active Control Mode" 2 "StandBy Mode" 1 "PassiveMode" 0 "OFF Mode" ;
VAL_ 814 ACC_Drive_Off_Req_S 1 "request" 0 "norequest" ;
VAL_ 814 ACC_DecTo_Stop_Req_S 1 "request" 0 "norequest" ;
VAL_ 814 ACC_Minimum_Braking_S 1 "demand" 0 "nodemand" ;
VAL_ 814 Brake_Preferred_S 1 "demand" 0 "nodemand" ;
VAL_ 814 ACC_Mode_S 7 "Failuremode" 6 "Standstill" 5 "Override" 4 "BrakeOnlymode" 3 "ActiveControlmode" 2 "StandBymode" 1 "Passivemode" 0 "OFF" ;
VAL_ 814 ESP_VLC_Shut_Down_Request_S 3 "Initial" 2 "Immediateoff" 1 "Fastoff" 0 "Softoff" ;
VAL_ 815 MRR_MRC_Request_S 1 "Request" 0 "No request" ;
VAL_ 815 MRR_SOS_Request_S 1 "Request" 0 "No request" ;
VAL_ 815 SeatbeltControl_Request_S 3 "  Reserved" 2 "Request to tension" 1 "Request to Shock" 0 "No Request" ;
VAL_ 815 ELK_OT_status_S 3 "Failure" 2 "Ative" 1 "Passive" 0 "OFF" ;
VAL_ 815 ABA_Level_S 3 "level3" 2 "level2" 1 "level1" 0 "level0" ;
VAL_ 815 ABA_Available_S 1 "demand" 0 "nodemand" ;
VAL_ 815 Req_EBA_Decel_Ctrl_S 1 "demand" 0 "nodemand" ;
VAL_ 815 ESP_Prefill_Req_S 1 "demand" 0 "nodemand" ;
VAL_ 815 AWB_Request_S 1 "demand" 0 "nodemand" ;
VAL_ 815 AEB_DecCtrl_Request_S 1 "demand" 0 "nodemand" ;
VAL_ 815 AWB_Level_S 4 "level4" 3 "level3" 2 "level2" 1 "level1" 0 "nolevel" ;
VAL_ 815 Req_ESC_Ctrl_Veh_S 1 "Nothold" 0 "Hold" ;
VAL_ 815 ISLC_Sts_S 1 "ON" 0 "OFF" ;
VAL_ 815 ELK_status_S 3 "Failure" 2 "Active" 1 "Passive" 0 "OFF" ;
VAL_ 815 ISLC_Warnning_S 1 "Request按set-操作" 0 "NoRequest" ;
VAL_ 815 ELK_Take_Over_Req_S 3 "warning-level3" 2 "warning-level2" 1 "warning-level1" 0 "inactive" ;
